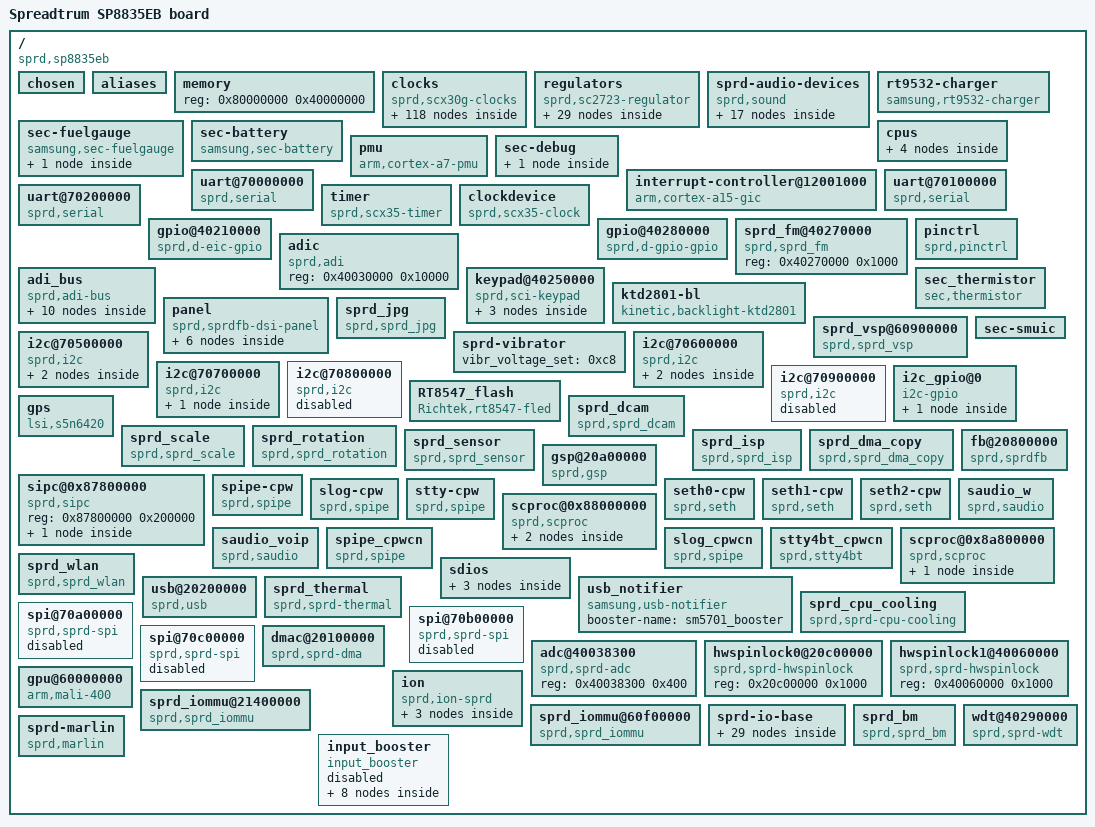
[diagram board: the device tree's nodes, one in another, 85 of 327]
/dts-v1/;

/memreserve/	0x0000000087800000 0x0000000000200000;
/memreserve/	0x0000000088000000 0x0000000001c00000;
/memreserve/	0x000000008a800000 0x0000000000201000;
/memreserve/	0x000000009f8ad000 0x0000000000465000;
/memreserve/	0x000000009fd12000 0x00000000002ee000;
/ {
	#address-cells = <0x01>;
	#size-cells = <0x01>;
	model = "Spreadtrum SP8835EB board";
	compatible = "sprd,sp8835eb";
	sprd,sc-id = <0x227e 0x00 0x20000>;
	interrupt-parent = <0x01>;

	chosen {
		bootargs = "loglevel=0 init=/init root=/dev/ram0 rw";
		linux,initrd-start = <0x85500000>;
		linux,initrd-end = <0x855a3212>;
	};

	aliases {
		serial0 = "/uart@70000000";
		serial1 = "/uart@70100000";
		serial2 = "/uart@70200000";
		i2c0 = "/i2c@70500000";
		i2c1 = "/i2c@70600000";
		i2c2 = "/i2c@70700000";
		i2c_gpio4 = "/i2c_gpio@0";
		lcd0 = "/fb@20800000";
		spi0 = "/spi@70a00000";
		spi1 = "/spi@70b00000";
		spi2 = "/spi@70c00000";
		hwspinlock0 = "/hwspinlock0@20c00000";
		hwspinlock1 = "/hwspinlock1@40060000";
	};

	memory {
		#address-cells = <0x01>;
		#size-cells = <0x01>;
		device_type = "memory";
		reg = <0x80000000 0x40000000>;
	};

	clocks {
		compatible = "sprd,scx30g-clocks";
		#address-cells = <0x01>;
		#size-cells = <0x01>;

		ext_26m {
			compatible = "sprd,fixed-clock";
			#clock-cells = <0x00>;
			clock-frequency = <0x18cba80>;
			clock-output-names = "ext_26m";
			linux,phandle = <0x09>;
			phandle = <0x09>;
		};

		ext_32k {
			compatible = "sprd,fixed-clock";
			#clock-cells = <0x00>;
			clock-frequency = <0x8000>;
			clock-output-names = "ext_32k";
			linux,phandle = <0x12>;
			phandle = <0x12>;
		};

		clk_mpll {
			compatible = "sprd,adjustable-pll-clock";
			#clock-cells = <0x00>;
			reg = <0x402e3070 0x7ff 0x402b0094 0x01>;
			clock-output-names = "clk_mpll";
			linux,phandle = <0x03>;
			phandle = <0x03>;
		};

		clk_dpll {
			compatible = "sprd,adjustable-pll-clock";
			#clock-cells = <0x00>;
			reg = <0x402e3074 0x7ff 0x402b0098 0x01>;
			clock-output-names = "clk_dpll";
			linux,phandle = <0x04>;
			phandle = <0x04>;
		};

		clk_tdpll {
			compatible = "sprd,adjustable-pll-clock";
			#clock-cells = <0x00>;
			reg = <0x402e3078 0x7ff 0x402b009c 0x01>;
			clock-output-names = "clk_tdpll";
			linux,phandle = <0x07>;
			phandle = <0x07>;
		};

		clk_wpll {
			compatible = "sprd,adjustable-pll-clock";
			#clock-cells = <0x00>;
			reg = <0x402e301c 0x7ff 0x402b00a0 0x01>;
			clock-output-names = "clk_wpll";
			linux,phandle = <0x02>;
			phandle = <0x02>;
		};

		clk_cpll {
			compatible = "sprd,adjustable-pll-clock";
			#clock-cells = <0x00>;
			reg = <0x402e307c 0x7ff 0x402b00a4 0x01>;
			clock-output-names = "clk_cpll";
			linux,phandle = <0x06>;
			phandle = <0x06>;
		};

		clk_wifipll {
			compatible = "sprd,adjustable-pll-clock";
			#clock-cells = <0x00>;
			reg = <0x402e3080 0x7ff 0x402b00a8 0x01>;
			clock-output-names = "clk_wifipll";
			linux,phandle = <0x05>;
			phandle = <0x05>;
		};

		clk_460m8 {
			compatible = "sprd,fixed-factor-clock";
			#clock-cells = <0x00>;
			clock-mult = <0x01>;
			clock-div = <0x02>;
			clocks = <0x02>;
			clock-output-names = "clk_460m8";
			linux,phandle = <0x21>;
			phandle = <0x21>;
		};

		clk_300m {
			compatible = "sprd,fixed-factor-clock";
			#clock-cells = <0x00>;
			clock-mult = <0x01>;
			clock-div = <0x03>;
			clocks = <0x03>;
			clock-output-names = "clk_300m";
		};

		clk_37m5 {
			compatible = "sprd,fixed-factor-clock";
			#clock-cells = <0x00>;
			clock-mult = <0x01>;
			clock-div = <0x18>;
			clocks = <0x03>;
			clock-output-names = "clk_37m5";
			linux,phandle = <0x16>;
			phandle = <0x16>;
		};

		clk_66m_d {
			compatible = "sprd,fixed-factor-clock";
			#clock-cells = <0x00>;
			clock-mult = <0x01>;
			clock-div = <0x08>;
			clocks = <0x04>;
			clock-output-names = "clk_66m_d";
		};

		clk_51m2_w {
			compatible = "sprd,fixed-factor-clock";
			#clock-cells = <0x00>;
			clock-mult = <0x01>;
			clock-div = <0x12>;
			clocks = <0x02>;
			clock-output-names = "clk_51m2_w";
			linux,phandle = <0x15>;
			phandle = <0x15>;
		};

		clk_40m_wf1 {
			compatible = "sprd,fixed-factor-clock";
			#clock-cells = <0x00>;
			clock-mult = <0x01>;
			clock-div = <0x16>;
			clocks = <0x05>;
			clock-output-names = "clk_40m_wf1";
			linux,phandle = <0x17>;
			phandle = <0x17>;
		};

		clk_312m {
			compatible = "sprd,fixed-factor-clock";
			#clock-cells = <0x00>;
			clock-mult = <0x01>;
			clock-div = <0x02>;
			clocks = <0x06>;
			clock-output-names = "clk_312m";
			linux,phandle = <0x1c>;
			phandle = <0x1c>;
		};

		clk_208m {
			compatible = "sprd,fixed-factor-clock";
			#clock-cells = <0x00>;
			clock-mult = <0x01>;
			clock-div = <0x03>;
			clocks = <0x06>;
			clock-output-names = "clk_208m";
			linux,phandle = <0x20>;
			phandle = <0x20>;
		};

		clk_104m {
			compatible = "sprd,fixed-factor-clock";
			#clock-cells = <0x00>;
			clock-mult = <0x01>;
			clock-div = <0x06>;
			clocks = <0x06>;
			clock-output-names = "clk_104m";
		};

		clk_52m {
			compatible = "sprd,fixed-factor-clock";
			#clock-cells = <0x00>;
			clock-mult = <0x01>;
			clock-div = <0x0c>;
			clocks = <0x06>;
			clock-output-names = "clk_52m";
			linux,phandle = <0x14>;
			phandle = <0x14>;
		};

		clk_768m {
			compatible = "sprd,fixed-factor-clock";
			#clock-cells = <0x00>;
			clock-mult = <0x01>;
			clock-div = <0x02>;
			clocks = <0x07>;
			clock-output-names = "clk_768m";
			linux,phandle = <0x08>;
			phandle = <0x08>;
		};

		clk_512m {
			compatible = "sprd,fixed-factor-clock";
			#clock-cells = <0x00>;
			clock-mult = <0x01>;
			clock-div = <0x03>;
			clocks = <0x07>;
			clock-output-names = "clk_512m";
			linux,phandle = <0x22>;
			phandle = <0x22>;
		};

		clk_384m {
			compatible = "sprd,fixed-factor-clock";
			#clock-cells = <0x00>;
			clock-mult = <0x01>;
			clock-div = <0x02>;
			clocks = <0x08>;
			clock-output-names = "clk_384m";
			linux,phandle = <0x1d>;
			phandle = <0x1d>;
		};

		clk_256m {
			compatible = "sprd,fixed-factor-clock";
			#clock-cells = <0x00>;
			clock-mult = <0x01>;
			clock-div = <0x03>;
			clocks = <0x08>;
			clock-output-names = "clk_256m";
			linux,phandle = <0x1b>;
			phandle = <0x1b>;
		};

		clk_192m {
			compatible = "sprd,fixed-factor-clock";
			#clock-cells = <0x00>;
			clock-mult = <0x01>;
			clock-div = <0x04>;
			clocks = <0x08>;
			clock-output-names = "clk_192m";
			linux,phandle = <0x1a>;
			phandle = <0x1a>;
		};

		clk_153m6 {
			compatible = "sprd,fixed-factor-clock";
			#clock-cells = <0x00>;
			clock-mult = <0x01>;
			clock-div = <0x05>;
			clocks = <0x08>;
			clock-output-names = "clk_153m6";
			linux,phandle = <0x0d>;
			phandle = <0x0d>;
		};

		clk_128m {
			compatible = "sprd,fixed-factor-clock";
			#clock-cells = <0x00>;
			clock-mult = <0x01>;
			clock-div = <0x06>;
			clocks = <0x08>;
			clock-output-names = "clk_128m";
			linux,phandle = <0x0c>;
			phandle = <0x0c>;
		};

		clk_96m {
			compatible = "sprd,fixed-factor-clock";
			#clock-cells = <0x00>;
			clock-mult = <0x01>;
			clock-div = <0x08>;
			clocks = <0x08>;
			clock-output-names = "clk_96m";
			linux,phandle = <0x0b>;
			phandle = <0x0b>;
		};

		clk_76m8 {
			compatible = "sprd,fixed-factor-clock";
			#clock-cells = <0x00>;
			clock-mult = <0x01>;
			clock-div = <0x0a>;
			clocks = <0x08>;
			clock-output-names = "clk_76m8";
			linux,phandle = <0x0e>;
			phandle = <0x0e>;
		};

		clk_64m {
			compatible = "sprd,fixed-factor-clock";
			#clock-cells = <0x00>;
			clock-mult = <0x01>;
			clock-div = <0x0c>;
			clocks = <0x08>;
			clock-output-names = "clk_64m";
			linux,phandle = <0x11>;
			phandle = <0x11>;
		};

		clk_51m2 {
			compatible = "sprd,fixed-factor-clock";
			#clock-cells = <0x00>;
			clock-mult = <0x01>;
			clock-div = <0x0f>;
			clocks = <0x08>;
			clock-output-names = "clk_51m2";
			linux,phandle = <0x10>;
			phandle = <0x10>;
		};

		clk_48m {
			compatible = "sprd,fixed-factor-clock";
			#clock-cells = <0x00>;
			clock-mult = <0x01>;
			clock-div = <0x10>;
			clocks = <0x08>;
			clock-output-names = "clk_48m";
			linux,phandle = <0x13>;
			phandle = <0x13>;
		};

		clk_38m4 {
			compatible = "sprd,fixed-factor-clock";
			#clock-cells = <0x00>;
			clock-mult = <0x01>;
			clock-div = <0x14>;
			clocks = <0x08>;
			clock-output-names = "clk_38m4";
			linux,phandle = <0x0f>;
			phandle = <0x0f>;
		};

		clk_24m {
			compatible = "sprd,fixed-factor-clock";
			#clock-cells = <0x00>;
			clock-mult = <0x01>;
			clock-div = <0x20>;
			clocks = <0x08>;
			clock-output-names = "clk_24m";
			linux,phandle = <0x1f>;
			phandle = <0x1f>;
		};

		clk_12m {
			compatible = "sprd,fixed-factor-clock";
			#clock-cells = <0x00>;
			clock-mult = <0x01>;
			clock-div = <0x40>;
			clocks = <0x08>;
			clock-output-names = "clk_12m";
			linux,phandle = <0x1e>;
			phandle = <0x1e>;
		};

		clk_mcu {
			compatible = "sprd,composite-dev-clock";
			#clock-cells = <0x00>;
			reg = <0x20d03000 0x07 0x20d03000 0x70>;
			clocks = <0x09 0x04 0x06 0x08 0x05 0x02 0x03>;
			clock-output-names = "clk_mcu";
			linux,phandle = <0x0a>;
			phandle = <0x0a>;
		};

		clk_ca7_axi {
			compatible = "sprd,divider-clock";
			#clock-cells = <0x00>;
			reg = <0x20d03000 0x700>;
			clocks = <0x0a>;
			clock-output-names = "clk_ca7_axi";
		};

		clk_ca7_dbg {
			compatible = "sprd,divider-clock";
			#clock-cells = <0x00>;
			reg = <0x20d03000 0x70000 0x20d00014 0x100>;
			clocks = <0x0a>;
			clock-output-names = "clk_ca7_dbg";
		};

		clk_emc {
			compatible = "sprd,composite-dev-clock";
			#clock-cells = <0x00>;
			reg = <0x402d0024 0x03 0x402d0024 0x300>;
			clocks = <0x09 0x06 0x07 0x04>;
			clock-output-names = "clk_emc";
		};

		clk_pub_ahb {
			compatible = "sprd,muxed-clock";
			#clock-cells = <0x00>;
			reg = <0x402d0020 0x03>;
			clocks = <0x09 0x0b 0x0c 0x0d>;
			clock-output-names = "clk_pub_ahb";
		};

		clk_aon_apb {
			compatible = "sprd,composite-dev-clock";
			#clock-cells = <0x00>;
			reg = <0x402d0028 0x03 0x402d0028 0x300>;
			clocks = <0x09 0x0e 0x0b 0x0c>;
			clock-output-names = "clk_aon_apb";
			linux,phandle = <0x19>;
			phandle = <0x19>;
		};

		clk_adi {
			compatible = "sprd,muxed-clock";
			#clock-cells = <0x00>;
			reg = <0x402d0034 0x03 0x402e0000 0x10000>;
			clocks = <0x09 0x0f 0x10 0x11>;
			clock-output-names = "clk_adi";
		};

		clk_aux0 {
			compatible = "sprd,composite-dev-clock";
			#clock-cells = <0x00>;
			reg = <0x402e3020 0x07 0x402e3020 0xf0000 0x402e0004 0x04>;
			clocks = <0x12 0x09 0x09 0x13 0x14 0x15 0x16 0x17>;
			clock-output-names = "clk_aux0";
		};

		clk_aux1 {
			compatible = "sprd,composite-dev-clock";
			#clock-cells = <0x00>;
			reg = <0x402e3020 0x70 0x402e3020 0xf00000 0x402e0004 0x08>;
			clocks = <0x12 0x09 0x09 0x13 0x14 0x15 0x16 0x17>;
			clock-output-names = "clk_aux1";
		};

		clk_aux2 {
			compatible = "sprd,composite-dev-clock";
			#clock-cells = <0x00>;
			reg = <0x402e3020 0x700 0x402e3020 0xf000000 0x402e0004 0x10>;
			clocks = <0x12 0x09 0x09 0x13 0x14 0x15 0x16 0x17>;
			clock-output-names = "clk_aux2";
		};

		clk_probe {
			compatible = "sprd,composite-dev-clock";
			#clock-cells = <0x00>;
			reg = <0x402e3020 0x7000 0x402e3020 0xf0000000 0x402e0004 0x20>;
			clocks = <0x12 0x09 0x09 0x13 0x14 0x15 0x16 0x17>;
			clock-output-names = "clk_probe";
		};

		clk_pwm0 {
			compatible = "sprd,muxed-clock";
			#clock-cells = <0x00>;
			reg = <0x402d0038 0x01 0x402e0000 0x10>;
			clocks = <0x12 0x09>;
			clock-output-names = "clk_pwm0";
		};

		clk_pwm1 {
			compatible = "sprd,muxed-clock";
			#clock-cells = <0x00>;
			reg = <0x402d003c 0x01 0x402e0000 0x20>;
			clocks = <0x12 0x09>;
			clock-output-names = "clk_pwm1";
		};

		clk_pwm2 {
			compatible = "sprd,muxed-clock";
			#clock-cells = <0x00>;
			reg = <0x402d0040 0x01 0x402e0000 0x40>;
			clocks = <0x12 0x09>;
			clock-output-names = "clk_pwm2";
		};

		clk_pwm3 {
			compatible = "sprd,muxed-clock";
			#clock-cells = <0x00>;
			reg = <0x402d0044 0x01 0x402e0000 0x80>;
			clocks = <0x12 0x09>;
			clock-output-names = "clk_pwm3";
		};

		clk_thm {
			compatible = "sprd,muxed-clock";
			#clock-cells = <0x00>;
			reg = <0x402d0048 0x01 0x402e0004 0x02>;
			clocks = <0x12 0x09>;
			clock-output-names = "clk_thm";
		};

		clk_efuse {
			compatible = "sprd,gate-clock";
			#clock-cells = <0x00>;
			reg = <0x402e0000 0x2000>;
			clocks = <0x09>;
			clock-output-names = "clk_efuse";
		};

		clk_mspi {
			compatible = "sprd,muxed-clock";
			#clock-cells = <0x00>;
			reg = <0x402d0054 0x03 0x402e0000 0x800000>;
			clocks = <0x09 0x14 0x0e 0x0b>;
			clock-output-names = "clk_mspi";
		};

		clk_i2c {
			compatible = "sprd,muxed-clock";
			#clock-cells = <0x00>;
			reg = <0x402d0058 0x03 0x402e0000 0x80000000>;
			clocks = <0x09 0x13 0x10 0x0d>;
			clock-output-names = "clk_i2c";
		};

		clk_avs0 {
			compatible = "sprd,muxed-clock";
			#clock-cells = <0x00>;
			reg = <0x402d005c 0x03 0x402e0000 0x40>;
			clocks = <0x09 0x13 0x10 0x0b>;
			clock-output-names = "clk_avs0";
		};

		clk_avs1 {
			compatible = "sprd,muxed-clock";
			#clock-cells = <0x00>;
			reg = <0x402d0060 0x03 0x402e0000 0x80>;
			clocks = <0x09 0x13 0x10 0x0b>;
			clock-output-names = "clk_avs1";
		};

		clk_aud {
			compatible = "sprd,gate-clock";
			#clock-cells = <0x00>;
			reg = <0x402e0000 0x40000>;
			clocks = <0x09>;
			clock-output-names = "clk_aud";
		};

		clk_audif {
			compatible = "sprd,muxed-clock";
			#clock-cells = <0x00>;
			reg = <0x402d002c 0x03 0x402e0000 0x20000>;
			clocks = <0x09 0x0f 0x10>;
			clock-output-names = "clk_audif";
		};

		clk_vbc {
			compatible = "sprd,gate-clock";
			#clock-cells = <0x00>;
			reg = <0x402e0000 0x80000>;
			clocks = <0x09>;
			clock-output-names = "clk_vbc";
		};

		clk_ca7_dap {
			compatible = "sprd,muxed-clock";
			#clock-cells = <0x00>;
			reg = <0x402d004c 0x03 0x402e0000 0x40000000>;
			clocks = <0x09 0x0e 0x0c 0x0d>;
			clock-output-names = "clk_ca7_dap";
		};

		clk_ca7_ts {
			compatible = "sprd,muxed-clock";
			#clock-cells = <0x00>;
			reg = <0x402d0050 0x03 0x402e0000 0x10000000>;
			clocks = <0x12 0x09 0x0c 0x0d>;
			clock-output-names = "clk_ca7_ts";
		};

		clk_fm_in {
			compatible = "sprd,fixed-clock";
			#clock-cells = <0x00>;
			clock-frequency = <0x3d09000>;
			clock-output-names = "clk_fm_in";
			linux,phandle = <0x18>;
			phandle = <0x18>;
		};

		clk_fm {
			compatible = "sprd,gate-clock";
			#clock-cells = <0x00>;
			reg = <0x402e0000 0x02>;
			clocks = <0x18>;
			clock-output-names = "clk_fm";
		};

		clk_disp_emc {
			compatible = "sprd,gate-clock";
			#clock-cells = <0x00>;
			reg = <0x402e0004 0x800>;
			clocks = <0x19>;
			clock-output-names = "clk_disp_emc";
			linux,phandle = <0x43>;
			phandle = <0x43>;
		};

		clk_zip_emc {
			compatible = "sprd,gate-clock";
			#clock-cells = <0x00>;
			reg = <0x402e0004 0x1000>;
			clocks = <0x19>;
			clock-output-names = "clk_zip_emc";
		};

		clk_gsp_emc {
			compatible = "sprd,gate-clock";
			#clock-cells = <0x00>;
			reg = <0x402e0004 0x2000>;
			clocks = <0x19>;
			clock-output-names = "clk_gsp_emc";
			linux,phandle = <0x46>;
			phandle = <0x46>;
		};

		clk_ap_ahb {
			compatible = "sprd,muxed-clock";
			#clock-cells = <0x00>;
			reg = <0x71200020 0x03>;
			clocks = <0x09 0x0e 0x0c 0x1a>;
			clock-output-names = "clk_ap_ahb";
		};

		clk_ap_apb {
			compatible = "sprd,muxed-clock";
			#clock-cells = <0x00>;
			reg = <0x71200024 0x03>;
			clocks = <0x09 0x11 0x0b 0x0c>;
			clock-output-names = "clk_ap_apb";
		};

		clk_gsp {
			compatible = "sprd,muxed-clock";
			#clock-cells = <0x00>;
			reg = <0x71200028 0x03 0x20d00000 0x08>;
			clocks = <0x0b 0x0d 0x1a 0x1b>;
			clock-output-names = "clk_gsp";
			linux,phandle = <0x45>;
			phandle = <0x45>;
		};

		clk_dispc0 {
			compatible = "sprd,composite-dev-clock";
			#clock-cells = <0x00>;
			reg = <0x7120002c 0x03 0x7120002c 0x700 0x20d00000 0x02>;
			clocks = <0x0d 0x1a 0x1b 0x1c>;
			clock-output-names = "clk_dispc0";
			linux,phandle = <0x40>;
			phandle = <0x40>;
		};

		clk_dispc0_dbi {
			compatible = "sprd,composite-dev-clock";
			#clock-cells = <0x00>;
			reg = <0x71200030 0x03 0x71200030 0x700 0x20d00000 0x02>;
			clocks = <0x0c 0x0d 0x1a 0x1b>;
			clock-output-names = "clk_dispc0_dbi";
			linux,phandle = <0x41>;
			phandle = <0x41>;
		};

		clk_dispc0_dpi {
			compatible = "sprd,composite-dev-clock";
			#clock-cells = <0x00>;
			reg = <0x71200034 0x03 0x71200034 0xff00 0x20d00000 0x02>;
			clocks = <0x0c 0x0d 0x1a 0x1d>;
			clock-output-names = "clk_dispc0_dpi";
			linux,phandle = <0x42>;
			phandle = <0x42>;
		};

		clk_dispc1 {
			compatible = "sprd,composite-dev-clock";
			#clock-cells = <0x00>;
			reg = <0x71200038 0x03 0x71200038 0x700 0x20d00000 0x04>;
			clocks = <0x0d 0x1a 0x1b 0x1c>;
			clock-output-names = "clk_dispc1";
		};

		clk_dispc1_dbi {
			compatible = "sprd,composite-dev-clock";
			#clock-cells = <0x00>;
			reg = <0x7120003c 0x03 0x7120003c 0x700 0x20d00000 0x04>;
			clocks = <0x0c 0x0d 0x1a 0x1b>;
			clock-output-names = "clk_dispc1_dbi";
		};

		clk_dispc1_dpi {
			compatible = "sprd,composite-dev-clock";
			#clock-cells = <0x00>;
			reg = <0x71200040 0x03 0x71200040 0xff00 0x20d00000 0x04>;
			clocks = <0x0c 0x0d 0x1a 0x1d>;
			clock-output-names = "clk_dispc1_dpi";
		};

		clk_nandc_ecc {
			compatible = "sprd,muxed-clock";
			#clock-cells = <0x00>;
			reg = <0x71200044 0x01 0x20d00000 0x80000 0x20d00000 0x20000>;
			clocks = <0x0d 0x1a>;
			clock-output-names = "clk_nandc_ecc";
		};

		clk_nandc_2x {
			compatible = "sprd,composite-dev-clock";
			#clock-cells = <0x00>;
			reg = <0x20d03038 0x03 0x20d03038 0x0c 0x20d00000 0xe0000>;
			clocks = <0x09 0x0d 0x1a 0x1b>;
			clock-output-names = "clk_nandc_2x";
		};

		clk_sdio0 {
			compatible = "sprd,composite-dev-clock";
			#clock-cells = <0x00>;
			reg = <0x71200048 0x03 0x71200048 0x700 0x20d00000 0x100>;
			clocks = <0x09 0x1b 0x1c 0x1a>;
			clock-output-names = "clk_sdio0";
			linux,phandle = <0x48>;
			phandle = <0x48>;
		};

		clk_sdio1 {
			compatible = "sprd,muxed-clock";
			#clock-cells = <0x00>;
			reg = <0x7120004c 0x03 0x20d00000 0x200>;
			clocks = <0x13 0x0e 0x0b 0x0c>;
			clock-output-names = "clk_sdio1";
			linux,phandle = <0x49>;
			phandle = <0x49>;
		};

		clk_sdio2 {
			compatible = "sprd,muxed-clock";
			#clock-cells = <0x00>;
			reg = <0x71200050 0x03 0x20d00000 0x400>;
			clocks = <0x13 0x0e 0x0b 0x0c>;
			clock-output-names = "clk_sdio2";
		};

		clk_emmc {
			compatible = "sprd,muxed-clock";
			#clock-cells = <0x00>;
			reg = <0x71200054 0x03 0x20d00000 0x800>;
			clocks = <0x09 0x1b 0x1c 0x1a>;
			clock-output-names = "clk_emmc";
			linux,phandle = <0x47>;
			phandle = <0x47>;
		};

		clk_gps {
			compatible = "sprd,muxed-clock";
			#clock-cells = <0x00>;
			reg = <0x71200058 0x01 0x20d00000 0x1000>;
			clocks = <0x11 0x0e>;
			clock-output-names = "clk_gps";
		};

		clk_usb_ref {
			compatible = "sprd,muxed-clock";
			#clock-cells = <0x00>;
			reg = <0x71200060 0x01 0x20d00000 0x10>;
			clocks = <0x1e 0x1f>;
			clock-output-names = "clk_usb_ref";
		};

		clk_uart0 {
			compatible = "sprd,composite-dev-clock";
			#clock-cells = <0x00>;
			reg = <0x71200064 0x03 0x71200064 0x700 0x71300000 0x2000>;
			clocks = <0x09 0x13 0x10 0x0b>;
			clock-output-names = "clk_uart0";
		};

		clk_uart1 {
			compatible = "sprd,composite-dev-clock";
			#clock-cells = <0x00>;
			reg = <0x71200068 0x03 0x71200068 0x700 0x71300000 0x4000>;
			clocks = <0x09 0x13 0x10 0x0b>;
			clock-output-names = "clk_uart1";
		};

		clk_uart2 {
			compatible = "sprd,composite-dev-clock";
			#clock-cells = <0x00>;
			reg = <0x7120006c 0x03 0x7120006c 0x700 0x71300000 0x8000>;
			clocks = <0x09 0x13 0x10 0x0b>;
			clock-output-names = "clk_uart2";
		};

		clk_uart3 {
			compatible = "sprd,composite-dev-clock";
			#clock-cells = <0x00>;
			reg = <0x71200070 0x03 0x71200070 0x700 0x71300000 0x10000>;
			clocks = <0x09 0x13 0x10 0x0b>;
			clock-output-names = "clk_uart3";
		};

		clk_uart4 {
			compatible = "sprd,composite-dev-clock";
			#clock-cells = <0x00>;
			reg = <0x71200074 0x03 0x71200074 0x700 0x71300000 0x20000>;
			clocks = <0x09 0x13 0x10 0x0b>;
			clock-output-names = "clk_uart4";
		};

		clk_i2c0 {
			compatible = "sprd,composite-dev-clock";
			#clock-cells = <0x00>;
			reg = <0x71200078 0x03 0x71200078 0x700 0x71300000 0x100>;
			clocks = <0x09 0x13 0x10 0x0d>;
			clock-output-names = "clk_i2c0";
		};

		clk_i2c1 {
			compatible = "sprd,composite-dev-clock";
			#clock-cells = <0x00>;
			reg = <0x7120007c 0x03 0x7120007c 0x700 0x71300000 0x200>;
			clocks = <0x09 0x13 0x10 0x0d>;
			clock-output-names = "clk_i2c1";
		};

		clk_i2c2 {
			compatible = "sprd,composite-dev-clock";
			#clock-cells = <0x00>;
			reg = <0x71200080 0x03 0x71200080 0x700 0x71300000 0x400>;
			clocks = <0x09 0x13 0x10 0x0d>;
			clock-output-names = "clk_i2c2";
		};

		clk_i2c3 {
			compatible = "sprd,composite-dev-clock";
			#clock-cells = <0x00>;
			reg = <0x71200084 0x03 0x71200084 0x700 0x71300000 0x800>;
			clocks = <0x09 0x13 0x10 0x0d>;
			clock-output-names = "clk_i2c3";
		};

		clk_i2c4 {
			compatible = "sprd,composite-dev-clock";
			#clock-cells = <0x00>;
			reg = <0x71200088 0x03 0x71200088 0x700 0x71300000 0x1000>;
			clocks = <0x09 0x13 0x10 0x0d>;
			clock-output-names = "clk_i2c4";
		};

		clk_spi0 {
			compatible = "sprd,composite-dev-clock";
			#clock-cells = <0x00>;
			reg = <0x7120008c 0x03 0x7120008c 0x700 0x71300000 0x20>;
			clocks = <0x09 0x0b 0x0d 0x1a>;
			clock-output-names = "clk_spi0";
		};

		clk_spi1 {
			compatible = "sprd,composite-dev-clock";
			#clock-cells = <0x00>;
			reg = <0x71200090 0x03 0x71200090 0x700 0x71300000 0x40>;
			clocks = <0x09 0x0b 0x0d 0x1a>;
			clock-output-names = "clk_spi1";
		};

		clk_spi2 {
			compatible = "sprd,composite-dev-clock";
			#clock-cells = <0x00>;
			reg = <0x71200094 0x03 0x71200094 0x700 0x71300000 0x80>;
			clocks = <0x09 0x0b 0x0d 0x1a>;
			clock-output-names = "clk_spi2";
			linux,phandle = <0x44>;
			phandle = <0x44>;
		};

		clk_iis0 {
			compatible = "sprd,composite-dev-clock";
			#clock-cells = <0x00>;
			reg = <0x71200098 0x03 0x71200098 0x700 0x71300000 0x02>;
			clocks = <0x09 0x0c 0x0d>;
			clock-output-names = "clk_iis0";
		};

		clk_iis1 {
			compatible = "sprd,composite-dev-clock";
			#clock-cells = <0x00>;
			reg = <0x7120009c 0x03 0x7120009c 0x700 0x71300000 0x04>;
			clocks = <0x09 0x0c 0x0d>;
			clock-output-names = "clk_iis1";
		};

		clk_iis2 {
			compatible = "sprd,composite-dev-clock";
			#clock-cells = <0x00>;
			reg = <0x712000a0 0x03 0x712000a0 0x700 0x71300000 0x08>;
			clocks = <0x09 0x0c 0x0d>;
			clock-output-names = "clk_iis2";
		};

		clk_iis3 {
			compatible = "sprd,composite-dev-clock";
			#clock-cells = <0x00>;
			reg = <0x712000a4 0x03 0x712000a4 0x700 0x71300000 0x10>;
			clocks = <0x09 0x0c 0x0d>;
			clock-output-names = "clk_iis3";
		};

		clk_zipenc {
			compatible = "sprd,muxed-clock";
			#clock-cells = <0x00>;
			reg = <0x712000a8 0x03 0x20d00000 0x100000>;
			clocks = <0x0b 0x0d 0x1a 0x1b>;
			clock-output-names = "clk_zipenc";
		};

		clk_zipdec {
			compatible = "sprd,muxed-clock";
			#clock-cells = <0x00>;
			reg = <0x712000ac 0x03 0x20d00000 0x200000>;
			clocks = <0x0b 0x0d 0x1a 0x1b>;
			clock-output-names = "clk_zipdec";
		};

		clk_gpu_axi {
			compatible = "sprd,gate-clock";
			#clock-cells = <0x00>;
			reg = <0x402e0000 0x8000000 0x402b0021 0x2000000>;
			clocks = <0x19>;
			clock-output-names = "clk_gpu_axi";
			linux,phandle = <0x4b>;
			phandle = <0x4b>;
		};

		clk_gpu {
			compatible = "sprd,composite-dev-clock";
			#clock-cells = <0x00>;
			reg = <0x60100004 0x07 0x60100004 0x30>;
			clocks = <0x0d 0x20 0x1b 0x1c 0x1d 0x21 0x22>;
			clock-output-names = "clk_gpu";
			linux,phandle = <0x4c>;
			phandle = <0x4c>;
		};

		clk_ccir_in {
			compatible = "sprd,fixed-clock";
			#clock-cells = <0x00>;
			clock-frequency = <0x3d09000>;
			clock-output-names = "clk_ccir_in";
			linux,phandle = <0x27>;
			phandle = <0x27>;
		};

		clk_mm {
			compatible = "sprd,gate-clock";
			#clock-cells = <0x00>;
			reg = <0x402e0000 0x2000000 0x402b001d 0x2000000>;
			clocks = <0x19>;
			clock-output-names = "clk_mm";
			linux,phandle = <0x23>;
			phandle = <0x23>;
		};

		clk_mm_ahb {
			compatible = "sprd,muxed-clock";
			#clock-cells = <0x00>;
			reg = <0x60e00020 0x03>;
			clocks = <0x09 0x0b 0x0c 0x0d>;
			clock-output-names = "clk_mm_ahb";
			mm-domain;
			linux,phandle = <0x25>;
			phandle = <0x25>;
		};

		clk_mm_axi {
			compatible = "sprd,gate-clock";
			#clock-cells = <0x00>;
			reg = <0x60d00008 0x80>;
			clocks = <0x23>;
			clock-output-names = "clk_mm_axi";
			#mm-domain;
			linux,phandle = <0x24>;
			phandle = <0x24>;
		};

		clk_mm_mtx_axi {
			compatible = "sprd,gate-clock";
			#clock-cells = <0x00>;
			reg = <0x60d00008 0x100>;
			clocks = <0x24>;
			clock-output-names = "clk_mm_mtx_axi";
			mm-domain;
		};

		clk_mmu {
			compatible = "sprd,gate-clock";
			#clock-cells = <0x00>;
			reg = <0x60d00000 0x80>;
			clocks = <0x25>;
			clock-output-names = "clk_mmu";
			mm-domain;
			linux,phandle = <0x4d>;
			phandle = <0x4d>;
		};

		clk_mm_ckg {
			compatible = "sprd,gate-clock";
			#clock-cells = <0x00>;
			reg = <0x60d00000 0x40>;
			clocks = <0x25>;
			clock-output-names = "clk_mm_ckg";
			mm-domain;
		};

		clk_jpg {
			compatible = "sprd,muxed-clock";
			#clock-cells = <0x00>;
			reg = <0x60e00038 0x03 0x60d00008 0x40 0x60d00000 0x20>;
			clocks = <0x0e 0x0c 0x1a 0x1b>;
			clock-output-names = "clk_jpg";
			mm-domain;
			linux,phandle = <0x3a>;
			phandle = <0x3a>;
		};

		clk_csi {
			compatible = "sprd,gate-clock";
			#clock-cells = <0x00>;
			reg = <0x60d00008 0x02 0x60d00000 0x10>;
			clocks = <0x25>;
			clock-output-names = "clk_csi";
			mm-domain;
			linux,phandle = <0x26>;
			phandle = <0x26>;
		};

		clk_dcam_mipi {
			compatible = "sprd,gate-clock";
			#clock-cells = <0x00>;
			reg = <0x60d00008 0x01>;
			clocks = <0x26>;
			clock-output-names = "clk_dcam_mipi";
			mm-domain;
			linux,phandle = <0x3e>;
			phandle = <0x3e>;
		};

		clk_vsp {
			compatible = "sprd,muxed-clock";
			#clock-cells = <0x00>;
			reg = <0x60e00030 0x03 0x60d00008 0x20 0x60d00000 0x08>;
			clocks = <0x0e 0x0c 0x1a>;
			clock-output-names = "clk_vsp";
			mm-domain;
			linux,phandle = <0x39>;
			phandle = <0x39>;
		};

		clk_isp {
			compatible = "sprd,muxed-clock";
			#clock-cells = <0x00>;
			reg = <0x60e00034 0x03 0x60d00008 0x10 0x60d00000 0x04>;
			clocks = <0x0e 0x0c 0x1a 0x1b>;
			clock-output-names = "clk_isp";
			mm-domain;
			linux,phandle = <0x3f>;
			phandle = <0x3f>;
		};

		clk_ccir {
			compatible = "sprd,muxed-clock";
			#clock-cells = <0x00>;
			reg = <0x60e00028 0x10000 0x60d00000 0x02>;
			clocks = <0x1f 0x27>;
			clock-output-names = "clk_ccir";
			mm-domain;
			linux,phandle = <0x3d>;
			phandle = <0x3d>;
		};

		clk_sensor {
			compatible = "sprd,composite-dev-clock";
			#clock-cells = <0x00>;
			reg = <0x60e00024 0x03 0x60e00024 0x700 0x60d00008 0x04>;
			clocks = <0x09 0x13 0x0e 0x0b>;
			clock-output-names = "clk_sensor";
			mm-domain;
			linux,phandle = <0x3c>;
			phandle = <0x3c>;
		};

		clk_dcam {
			compatible = "sprd,muxed-clock";
			#clock-cells = <0x00>;
			reg = <0x60e0002c 0x03 0x60d00008 0x08 0x60d00000 0x01>;
			clocks = <0x0e 0x0c 0x1a 0x1b>;
			clock-output-names = "clk_dcam";
			mm-domain;
			linux,phandle = <0x3b>;
			phandle = <0x3b>;
		};

		clk_vpp {
			compatible = "sprd,muxed-clock";
			#clock-cells = <0x00>;
			reg = <0x60e0003c 0x03 0x60d00008 0x200 0x60d00000 0x100>;
			clocks = <0x0e 0x0c 0x1a 0x1b>;
			clock-output-names = "clk_vpp";
			mm-domain;
		};
	};

	regulators {
		compatible = "sprd,sc2723-regulator";
		#address-cells = <0x01>;
		#size-cells = <0x01>;

		dummy {
		};

		vddcore {
			regulator-name = "vddcore";
			reg = <0x40038810 0x200 0x40038a00 0x3ff 0x400388c0 0x01>;
			regulator-cal-channel = <0x40038888 0x4000 0x0d>;
			regulator-default-microvolt = <0xdbba0>;
			regulator-step-microvolt = <0xc35>;
			regulator-min-microvolt = <0x927c0>;
			regulator-max-microvolt = <0x2faf08>;
			regulator-microvolt-offset = <0x00>;
			hide-offset = <0x47e>;
			default-on;
			dcdc;
		};

		vddarm {
			regulator-name = "vddarm";
			reg = <0x40038810 0x400 0x40038a04 0x3ff 0x400388c0 0x04>;
			regulator-cal-channel = <0x40038888 0x2000 0x0d>;
			regulator-default-microvolt = <0xdbba0>;
			regulator-step-microvolt = <0xc35>;
			regulator-min-microvolt = <0x927c0>;
			regulator-max-microvolt = <0x2faf08>;
			regulator-microvolt-offset = <0x00>;
			hide-offset = <0x47e>;
			default-on;
			dcdc;
		};

		vddmem {
			regulator-name = "vddmem";
			reg = <0x40038810 0x800 0x40038a08 0x3ff 0x400388c0 0x08>;
			regulator-cal-channel = <0x40038888 0x6000 0x0d>;
			regulator-default-microvolt = <0x124f80>;
			regulator-step-microvolt = <0xc35>;
			regulator-min-microvolt = <0x927c0>;
			regulator-max-microvolt = <0x2faf08>;
			regulator-microvolt-offset = <0x00>;
			hide-offset = <0x3e8>;
			dcdc;
		};

		vddgen {
			regulator-name = "vddgen";
			reg = <0x40038810 0x1000 0x40038a0c 0x3ff 0x400388c0 0x10>;
			regulator-cal-channel = <0x40038888 0x8000 0x0d>;
			regulator-default-microvolt = <0x249f00>;
			regulator-step-microvolt = <0xc35>;
			regulator-min-microvolt = <0x927c0>;
			regulator-max-microvolt = <0x2faf08>;
			regulator-microvolt-offset = <0x00>;
			hide-offset = <0x3e8>;
			default-on;
			dcdc;
		};

		vddrf {
			regulator-name = "vddrf";
			reg = <0x40038810 0x2000 0x40038a1c 0x3ff 0x400388c0 0x20>;
			regulator-cal-channel = <0x40038888 0xa000 0x0d>;
			regulator-default-microvolt = <0x16e360>;
			regulator-step-microvolt = <0xc35>;
			regulator-min-microvolt = <0x927c0>;
			regulator-max-microvolt = <0x2faf08>;
			regulator-microvolt-offset = <0x00>;
			hide-offset = <0x3e8>;
			default-on;
			dcdc;
		};

		vddwpa {
			regulator-name = "vddwpa";
			reg = <0x40038814 0x4000 0x40038a10 0x07 0x00 0x00>;
			regulator-cal-channel = <0x40038888 0xe000 0x0d>;
			regulator-default-microvolt = <0x2faf08>;
			regulator-step-microvolt = <0xc35>;
			regulator-min-microvolt = <0x2faf08>;
			regulator-max-microvolt = <0x33e140>;
			regulator-microvolt-offset = <0x00>;
			hide-offset = <0x3e8>;
			dcdc;
			status = "disabled";
		};

		vddcon {
			regulator-name = "vddcon";
			reg = <0x40038814 0x2000 0x40038a18 0x3ff 0x00 0x00>;
			regulator-cal-channel = <0x40038888 0xc000 0x0d>;
			regulator-default-microvolt = <0x186a00>;
			regulator-step-microvolt = <0xc35>;
			regulator-min-microvolt = <0x927c0>;
			regulator-max-microvolt = <0x2faf08>;
			regulator-microvolt-offset = <0x00>;
			hide-offset = <0x3e8>;
			dcdc;
		};

		vddrf0 {
			regulator-name = "vddrf0";
			reg = <0x40038810 0x100 0x40038818 0x7f00 0x400388c0 0x800>;
			regulator-cal-channel = <0x40038844 0x04 0x15>;
			regulator-default-microvolt = <0x1b7740>;
			regulator-step-microvolt = <0x186a>;
			regulator-min-microvolt = <0x118c30>;
			regulator-max-microvolt = <0x1da5d8>;
			regulator-microvolt-offset = <0x00>;
			hide-offset = <0x3e8>;
			default-on;
		};

		vddemmccore {
			regulator-name = "vddemmccore";
			reg = <0x40038810 0x80 0x40038834 0xff00 0x400388c0 0x80>;
			regulator-cal-channel = <0x40038844 0x60 0x17>;
			regulator-default-microvolt = <0x2dc6c0>;
			regulator-step-microvolt = <0x2710>;
			regulator-min-microvolt = <0x124f80>;
			regulator-max-microvolt = <0x395f80>;
			regulator-microvolt-offset = <0x00>;
			hide-offset = <0x3e8>;
			default-on;
		};

		vddgen1 {
			regulator-name = "vddgen1";
			reg = <0x40038810 0x40 0x40038824 0x7f00 0x400388c0 0x1000>;
			regulator-cal-channel = <0x40038844 0x05 0x15>;
			regulator-default-microvolt = <0x1b7740>;
			regulator-step-microvolt = <0x186a>;
			regulator-min-microvolt = <0x118c30>;
			regulator-max-microvolt = <0x1dc130>;
			regulator-microvolt-offset = <0x00>;
			hide-offset = <0x3e8>;
			default-on;
		};

		vddgen0 {
			regulator-name = "vddgen0";
			reg = <0x40038810 0x10 0x40038820 0x7f 0x400388c0 0x2000>;
			regulator-cal-channel = <0x40038844 0x06 0x15>;
			regulator-default-microvolt = <0x1b7740>;
			regulator-step-microvolt = <0x186a>;
			regulator-min-microvolt = <0x118c30>;
			regulator-max-microvolt = <0x1dc130>;
			regulator-microvolt-offset = <0x00>;
			hide-offset = <0x3e8>;
			default-on;
		};

		vdddcxo {
			regulator-name = "vdddcxo";
			reg = <0x40038810 0x20 0x40038838 0xff00 0x400388c0 0x100>;
			regulator-cal-channel = <0x40038844 0x80 0x17>;
			regulator-default-microvolt = <0x1b7740>;
			regulator-step-microvolt = <0x2710>;
			regulator-min-microvolt = <0x124f80>;
			regulator-max-microvolt = <0x395f80>;
			regulator-microvolt-offset = <0x00>;
			hide-offset = <0x3e8>;
			default-on;
		};

		vdd25 {
			regulator-name = "vdd25";
			reg = <0x40038810 0x08 0x40038840 0xff 0x400388c0 0x40>;
			regulator-cal-channel = <0x40038844 0x100 0x16>;
			regulator-default-microvolt = <0x2ab980>;
			regulator-step-microvolt = <0x2710>;
			regulator-min-microvolt = <0x124f80>;
			regulator-max-microvolt = <0x395f80>;
			regulator-microvolt-offset = <0x00>;
			hide-offset = <0x3e8>;
		};

		vdd28 {
			regulator-name = "vdd28";
			reg = <0x40038810 0x04 0x40038824 0xff 0x400388c0 0x200>;
			regulator-cal-channel = <0x40038844 0xc0 0x17>;
			regulator-default-microvolt = <0x2ab980>;
			regulator-step-microvolt = <0x2710>;
			regulator-min-microvolt = <0x124f80>;
			regulator-max-microvolt = <0x395f80>;
			regulator-microvolt-offset = <0x00>;
			hide-offset = <0x3e8>;
			default-on;
		};

		vdd18 {
			regulator-name = "vdd18";
			reg = <0x40038810 0x02 0x4003883c 0x7f00 0x400388c0 0x400>;
			regulator-cal-channel = <0x40038844 0x01 0x15>;
			regulator-default-microvolt = <0x1b7740>;
			regulator-step-microvolt = <0x186a>;
			regulator-min-microvolt = <0x118c30>;
			regulator-max-microvolt = <0x1dc130>;
			regulator-microvolt-offset = <0x00>;
			hide-offset = <0x3e8>;
			default-on;
		};

		vddwifipa {
			regulator-name = "vddwifipa";
			reg = <0x40038814 0x800 0x40038818 0xff 0x00 0x00>;
			regulator-cal-channel = <0x40038844 0x20 0x17>;
			regulator-default-microvolt = <0x1b7740>;
			regulator-step-microvolt = <0x2710>;
			regulator-min-microvolt = <0x124f80>;
			regulator-max-microvolt = <0x395f80>;
			regulator-microvolt-offset = <0x00>;
			hide-offset = <0x3e8>;
		};

		vddsdcore {
			regulator-name = "vddsdcore";
			reg = <0x40038814 0x400 0x40038830 0xff00 0x00 0x00>;
			regulator-cal-channel = <0x40038844 0xa0 0x17>;
			regulator-default-microvolt = <0x2dc6c0>;
			regulator-step-microvolt = <0x2710>;
			regulator-min-microvolt = <0x124f80>;
			regulator-max-microvolt = <0x395f80>;
			regulator-microvolt-offset = <0x00>;
			hide-offset = <0x3e8>;
		};

		vddsdio {
			regulator-name = "vddsdio";
			reg = <0x40038814 0x01 0x40038828 0xff 0x00 0x00>;
			regulator-cal-channel = <0x40038844 0x08 0x1d>;
			regulator-default-microvolt = <0x2dc6c0>;
			regulator-step-microvolt = <0x2710>;
			regulator-min-microvolt = <0x124f80>;
			regulator-max-microvolt = <0x395f80>;
			regulator-microvolt-offset = <0x00>;
			hide-offset = <0x3e8>;
		};

		vddsim0 {
			regulator-name = "vddsim0";
			reg = <0x40038814 0x02 0x40038828 0xff00 0x00 0x00>;
			regulator-cal-channel = <0x40038844 0x500 0x16>;
			regulator-default-microvolt = <0x1b7740>;
			regulator-step-microvolt = <0x2710>;
			regulator-min-microvolt = <0x124f80>;
			regulator-max-microvolt = <0x395f80>;
			regulator-microvolt-offset = <0x00>;
			hide-offset = <0x3e8>;
			status = "disabled";
		};

		vddsim1 {
			regulator-name = "vddsim1";
			reg = <0x40038814 0x04 0x4003882c 0xff 0x00 0x00>;
			regulator-cal-channel = <0x40038844 0x400 0x16>;
			regulator-default-microvolt = <0x1b7740>;
			regulator-step-microvolt = <0x2710>;
			regulator-min-microvolt = <0x124f80>;
			regulator-max-microvolt = <0x395f80>;
			regulator-microvolt-offset = <0x00>;
			hide-offset = <0x3e8>;
			status = "disabled";
		};

		vddsim2 {
			regulator-name = "vddsim2";
			reg = <0x40038814 0x08 0x4003882c 0xff00 0x00 0x00>;
			regulator-cal-channel = <0x40038844 0x300 0x16>;
			regulator-default-microvolt = <0x1b7740>;
			regulator-step-microvolt = <0x2710>;
			regulator-min-microvolt = <0x124f80>;
			regulator-max-microvolt = <0x395f80>;
			regulator-microvolt-offset = <0x00>;
			hide-offset = <0x3e8>;
		};

		vddcama {
			regulator-name = "vddcama";
			reg = <0x40038814 0x10 0x40038830 0xff 0x00 0x00>;
			regulator-cal-channel = <0x40038844 0x200 0x16>;
			regulator-default-microvolt = <0x2ab980>;
			regulator-step-microvolt = <0x2710>;
			regulator-min-microvolt = <0x124f80>;
			regulator-max-microvolt = <0x395f80>;
			regulator-microvolt-offset = <0x00>;
			hide-offset = <0x3e8>;
		};

		vddcamd {
			regulator-name = "vddcamd";
			reg = <0x40038814 0x20 0x4003881c 0x7f 0x00 0x00>;
			regulator-cal-channel = <0x40038844 0x02 0x15>;
			regulator-default-microvolt = <0x16e360>;
			regulator-step-microvolt = <0x186a>;
			regulator-min-microvolt = <0x118c30>;
			regulator-max-microvolt = <0x1dc130>;
			regulator-microvolt-offset = <0x00>;
			hide-offset = <0x3e8>;
		};

		vddcamio {
			regulator-name = "vddcamio";
			reg = <0x40038814 0x40 0x4003881c 0x7f00 0x00 0x00>;
			regulator-cal-channel = <0x40038844 0x03 0x15>;
			regulator-default-microvolt = <0x1b7740>;
			regulator-step-microvolt = <0x186a>;
			regulator-min-microvolt = <0x118c30>;
			regulator-max-microvolt = <0x1dc130>;
			regulator-microvolt-offset = <0x00>;
			hide-offset = <0x3e8>;
		};

		vddcammot {
			regulator-name = "vddcammot";
			reg = <0x40038814 0x80 0x40038834 0xff 0x00 0x00>;
			regulator-cal-channel = <0x40038844 0x40 0x17>;
			regulator-default-microvolt = <0x2ab980>;
			regulator-step-microvolt = <0x2710>;
			regulator-min-microvolt = <0x124f80>;
			regulator-max-microvolt = <0x395f80>;
			regulator-microvolt-offset = <0x00>;
			hide-offset = <0x3e8>;
		};

		vddusb {
			regulator-name = "vddusb";
			reg = <0x40038814 0x100 0x4003883c 0xff 0x00 0x00>;
			regulator-cal-channel = <0x40038844 0x10 0x1d>;
			regulator-default-microvolt = <0x325aa0>;
			regulator-step-microvolt = <0x2710>;
			regulator-min-microvolt = <0x124f80>;
			regulator-max-microvolt = <0x395f80>;
			regulator-microvolt-offset = <0x00>;
			hide-offset = <0x3e8>;
			linux,phandle = <0x4a>;
			phandle = <0x4a>;
		};

		vddkpled {
			regulator-name = "vddkpled";
			reg = <0x400388f4 0x100 0x400388f4 0xff 0x00 0x00>;
			regulator-cal-channel = <0x400388f8 0x3000 0x18>;
			regulator-default-microvolt = <0x325aa0>;
			regulator-step-microvolt = <0x2710>;
			regulator-min-microvolt = <0x124f80>;
			regulator-max-microvolt = <0x395f80>;
			regulator-microvolt-offset = <0x00>;
			hide-offset = <0x3e8>;
			linux,phandle = <0x38>;
			phandle = <0x38>;
		};

		vddvibr {
			regulator-name = "vddvibr";
			reg = <0x400388f8 0x100 0x400388f8 0xff 0x00 0x00>;
			regulator-cal-channel = <0x400388f8 0x2000 0x18>;
			regulator-default-microvolt = <0x2dc6c0>;
			regulator-step-microvolt = <0x2710>;
			regulator-min-microvolt = <0x124f80>;
			regulator-max-microvolt = <0x395f80>;
			regulator-microvolt-offset = <0x00>;
			hide-offset = <0x3e8>;
		};
	};

	sprd-audio-devices {
		compatible = "sprd,sound";
		#address-cells = <0x01>;
		#size-cells = <0x01>;

		sprd-codec {
			compatible = "sprd,sprd-codec";
			status = "okay";
			sprd,def_da_fs = <0xac44>;
			sprd,ap_irq = <0xa4>;
			sprd,dp_irq = <0x34>;
			sprd,reg_dp = <0x40000000 0x2000>;
			interrupt-parent = <0x28>;
			interrupts = <0x07 0x00>;
			sprd,audio_power_ver = <0x04>;
			linux,phandle = <0x2b>;
			phandle = <0x2b>;
		};

		sprd-codec-v3 {
			compatible = "sprd,sprd-codec-v3";
			status = "disable";
			sprd,def_da_fs = <0xac44>;
			sprd,ap_irq = <0xa4>;
			sprd,dp_irq = <0x34>;
			sprd,reg_dp = <0x40000000 0x2000>;
			interrupt-parent = <0x28>;
			interrupts = <0x07 0x00>;
			linux,phandle = <0x2d>;
			phandle = <0x2d>;
		};

		sprd-codec-v1 {
			compatible = "sprd,sprd-codec-v1";
			status = "disable";
			sprd,def_da_fs = <0xac44>;
			sprd,ap_irq = <0x67>;
			sprd,dp_irq = <0x3f>;
		};

		null-codec {
			compatible = "sprd,null-codec";
			linux,phandle = <0x30>;
			phandle = <0x30>;
		};

		vbc-r2p0 {
			compatible = "sprd,vbc-r2p0";
			status = "okay";
			sprd,reg_vbc = <0x40020000 0x20000>;
			linux,phandle = <0x2a>;
			phandle = <0x2a>;
		};

		vbc-r1p0 {
			compatible = "sprd,vbc-r1p0";
			status = "disable";
		};

		vaudio {
			compatible = "sprd,vaudio";
			linux,phandle = <0x29>;
			phandle = <0x29>;
		};

		bt-i2s-config {
			sprd,def_pcm_config;
		};

		fm-i2s-config {
		};

		i2s@0 {
			compatible = "sprd,i2s";
			status = "okay";
			sprd,dai_name = "i2s_bt_sco0";
			sprd,id = <0x00>;
			sprd,hw_port = <0x00>;
			sprd,base = <0x70d00000 0x100000>;
			sprd,dma_rx_no = <0x03>;
			sprd,dma_tx_no = <0x04>;
			sprd,config_type = "pcm";
			sprd,slave_timeout = <0xf11>;
			sprd,_hw_port = <0x00>;
			sprd,fs = <0x1f40>;
			sprd,bus_type = <0x01>;
			sprd,rtx_mode = <0x03>;
			sprd,byte_per_chan = <0x01>;
			sprd,slave_mode = <0x00>;
			sprd,lsb = <0x01>;
			sprd,lrck = <0x01>;
			sprd,low_for_left = <0x01>;
			sprd,clk_inv = <0x00>;
			sprd,pcm_short_frame = <0x01>;
			sprd,pcm_slot = <0x01>;
			sprd,pcm_cycle = <0x01>;
			sprd,tx_watermark = <0x0c>;
			sprd,rx_watermark = <0x14>;
			linux,phandle = <0x2e>;
			phandle = <0x2e>;
		};

		i2s@1 {
			compatible = "sprd,i2s";
			status = "okay";
			sprd,dai_name = "i2s_bt_sco1";
			sprd,id = <0x01>;
			sprd,hw_port = <0x01>;
			sprd,base = <0x70e00000 0x100000>;
			sprd,dma_rx_no = <0x05>;
			sprd,dma_tx_no = <0x06>;
			linux,phandle = <0x2f>;
			phandle = <0x2f>;
		};

		i2s@2 {
			compatible = "sprd,i2s";
			status = "disable";
			sprd,dai_name = "i2s_bt_sco2";
			sprd,id = <0x02>;
			sprd,hw_port = <0x02>;
			sprd,base = <0x70f00000 0x100000>;
			sprd,dma_rx_no = <0x07>;
			sprd,dma_tx_no = <0x08>;
		};

		i2s@3 {
			compatible = "sprd,i2s";
			status = "disable";
			sprd,dai_name = "i2s_bt_sco3";
			sprd,id = <0x03>;
			sprd,hw_port = <0x03>;
			sprd,base = <0x71000000 0x100000>;
			sprd,dma_rx_no = <0x09>;
			sprd,dma_tx_no = <0x0a>;
		};

		sprd-pcm-audio {
			compatible = "sprd,sprd-pcm";
			linux,phandle = <0x2c>;
			phandle = <0x2c>;
		};

		sound@0 {
			compatible = "sprd,vbc-r2p0-sprd-codec";
			sprd,model = "sprdphone";
			sprd,vaudio = <0x29>;
			sprd,vbc = <0x2a>;
			sprd,codec = <0x2b>;
			sprd,pcm = <0x2c>;
		};

		sound@1 {
			compatible = "sprd,vbc-r2p0-sprd-codec-v3";
			sprd,model = "sprdphone";
			sprd,vaudio = <0x29>;
			sprd,vbc = <0x2a>;
			sprd,codec = <0x2d>;
			sprd,pcm = <0x2c>;
		};

		sound@2 {
			compatible = "sprd,i2s-null-codec";
			sprd,model = "all-i2s";
			sprd,i2s = <0x2e 0x2f>;
			sprd,codec = <0x30>;
			sprd,pcm = <0x2c>;
		};
	};

	rt9532-charger {
		compatible = "samsung,rt9532-charger";
		chg-float-voltage = <0x10fe>;
		en-set = <0x31 0xa9 0x00>;
		chg-state = <0x31 0xea 0x00>;
		chg-det = <0x31 0xeb 0x00>;
	};

	sec-fuelgauge {
		compatible = "samsung,sec-fuelgauge";
		capacity-max = <0x3e8>;
		capacity-max-margin = <0x3e8>;
		capacity-min = <0x0a>;
		fg-irq-attr = <0x00>;
		fuel-alert-soc = <0x3e8>;
		temp_adc_channel = <0x00>;
		gpios = <0x32 0x00 0x00>;
		vmode = <0x00>;
		alm_soc = <0x05>;
		alm_vbat = <0xdac>;
		soft_vbat_uvlo = <0xc4e>;
		rint = <0x118>;
		cnom = <0x5be>;
		rsense_real = <0xd1>;
		rsense_spec = <0xc8>;
		relax_current = <0x32>;
		cnom_temp_tab = <0x401 0x5be 0x3f2 0x578 0x3e8 0x4b0 0x3de 0x384 0x3d4 0x2ee>;
		rint_temp_tab = <0x401 0x118 0x3f2 0x1ae 0x3e8 0x1f4>;
		ocv_table = <0x10cb 0x64 0x1090 0x5f 0x105a 0x5a 0x1027 0x55 0xff6 0x50 0xfcb 0x4b 0xf93 0x46 0xf78 0x41 0xf53 0x3c 0xf20 0x37 0xf00 0x32 0xeeb 0x2d 0xeda 0x28 0xecc 0x23 0xec3 0x1e 0xebc 0x19 0xeab 0x14 0xe8b 0x0f 0xe6e 0x0a 0xe66 0x05 0xd48 0x00>;

		sprd_fgu {
			compatible = "sprd,sprd_fgu";
			interrupt-parent = <0x28>;
			interrupts = <0x04 0x00>;
		};
	};

	sec-battery {
		compatible = "samsung,sec-battery";
		battery,vendor = "SDI SDI";
		battery,charger_name = "sec-charger";
		battery,fuelgauge_name = "sec-fuelgauge";
		battery,technology = <0x02>;
		battery,chip_vendor = "SPRD";
		battery,temp_adc_type = <0x01>;
		battery,polling_time = <0x0a 0x1e 0x1e 0x1e 0xe10>;
		battery,adc_check_count = <0x05>;
		battery,cable_check_type = <0x04>;
		battery,cable_source_type = <0x03>;
		battery,event_waiting_time = <0x258>;
		battery,polling_type = <0x01>;
		battery,monitor_initial_count = <0x03>;
		battery,battery_check_type = <0x05>;
		battery,check_count = <0x00>;
		battery,check_adc_max = <0x5a0>;
		battery,check_adc_min = <0x00>;
		battery,ovp_uvlo_check_type = <0x03>;
		battery,thermal_source = <0x02>;
		battery,temp_table_adc = <0x12e 0x1a7 0x22a 0x2f9 0x32b 0x355 0x3a1 0x3ce 0x416 0x49b 0x4d0 0x5a6 0x6ad 0x6f3 0x711 0x784 0x7b0 0x834 0x84f 0x8cc 0x8de 0x904 0x941>;
		battery,temp_table_data = <0x384 0x320 0x2bc 0x258 0x23a 0x226 0x1f4 0x1e0 0x1c2 0x190 0x17c 0x12c 0xc8 0xaa 0x96 0x64 0x50 0x14 0x00 0xffffffce 0xffffffba 0xffffff9c 0xffffff38>;
		battery,temp_check_type = <0x02>;
		battery,temp_check_count = <0x01>;
		battery,temp_high_threshold_event = <0x226>;
		battery,temp_high_recovery_event = <0x1f4>;
		battery,temp_low_threshold_event = <0xffffffce>;
		battery,temp_low_recovery_event = <0x00>;
		battery,temp_high_threshold_normal = <0x226>;
		battery,temp_high_recovery_normal = <0x1f4>;
		battery,temp_low_threshold_normal = <0xffffffce>;
		battery,temp_low_recovery_normal = <0x00>;
		battery,temp_high_threshold_lpm = <0x226>;
		battery,temp_high_recovery_lpm = <0x1f4>;
		battery,temp_low_threshold_lpm = <0xffffffce>;
		battery,temp_low_recovery_lpm = <0x00>;
		battery,full_check_type = <0x07>;
		battery,full_check_type_2nd = <0x00>;
		battery,full_check_count = <0x02>;
		battery,chg_gpio_full_check = <0x00>;
		battery,chg_polarity_full_check = <0x01>;
		battery,full_condition_type = <0x0f>;
		battery,full_condition_soc = <0x64>;
		battery,full_condition_vcell = <0x109a>;
		battery,recharge_check_count = <0x03>;
		battery,recharge_condition_type = <0x04>;
		battery,recharge_condition_soc = <0x5f>;
		battery,recharge_condition_vcell = <0x10ae>;
		battery,charging_total_time = <0x5460>;
		battery,recharging_total_time = <0x1518>;
		battery,charging_reset_time = <0x00>;
		battery,chg_irq_attr = <0x03>;
		battery,always_enable;
		battery,swelling_high_temp_block = <0x1c2>;
		battery,swelling_high_temp_recov = <0x190>;
		battery,swelling_low_temp_block = <0x64>;
		battery,swelling_low_temp_recov = <0x96>;
		battery,swelling_high_chg_current = <0x2bc>;
		battery,swelling_low_chg_current = <0x2bc>;
		battery,swelling_full_check_current_2nd = <0x00>;
		battery,swelling_drop_float_voltage = <0x1068>;
		battery,swelling_high_rechg_voltage = <0x1018>;
		battery,swelling_low_rechg_voltage = <0xfb4>;
		battery,swelling_block_time = <0x258>;
		battery,chg_float_voltage = <0x10fe>;
		battery,input_current_limit = <0x2bc 0x1cc 0x1cc 0x2bc 0x1cc 0x2bc 0x2bc 0x1cc 0x1cc 0x2bc 0x2bc 0x2bc 0x2bc 0x1cc 0x2bc 0x12c 0x2bc 0x2bc 0x12c 0x2bc 0x2bc 0x1cc 0x1cc>;
		battery,fast_charging_current = <0x3cf 0x00 0x3cf 0x3cf 0x3cf 0x3cf 0x3cf 0x3cf 0x00 0x3cf 0x3cf 0x3cf 0x3cf 0xffffffff 0x3cf 0x3cf 0x3cf 0x3cf 0x3cf 0x3cf 0x3cf 0x00 0x00>;
		battery,full_check_current_1st = <0xaf 0x00 0xaf 0xaf 0xaf 0xaf 0xaf 0xaf 0x00 0xaf 0xaf 0xaf 0xaf 0x00 0xaf 0xaf 0xaf 0xaf 0xaf 0xaf 0xaf 0x00 0x00>;
		battery,full_check_current_2nd = <0x708 0x00 0x708 0x708 0x708 0x708 0x708 0x708 0x00 0x708 0x708 0x708 0x708 0x00 0x708 0x708 0x708 0x708 0x708 0x708 0x708 0x00 0x00>;
	};

	cpus {
		#address-cells = <0x01>;
		#size-cells = <0x00>;

		cpu@f00 {
			device_type = "cpu";
			compatible = "arm,cortex-a7";
			reg = <0xf00>;
		};

		cpu@f01 {
			device_type = "cpu";
			compatible = "arm,cortex-a7";
			reg = <0xf01>;
		};

		cpu@f02 {
			device_type = "cpu";
			compatible = "arm,cortex-a7";
			reg = <0xf02>;
		};

		cpu@f03 {
			device_type = "cpu";
			compatible = "arm,cortex-a7";
			reg = <0xf03>;
		};
	};

	pmu {
		compatible = "arm,cortex-a7-pmu";
		interrupts = <0x00 0x5c 0x00 0x00 0x5d 0x00 0x00 0x5e 0x00 0x00 0x5f 0x00>;
	};

	sec-debug {

		crash_key {
			keys = "vol-down\0power\0power";
			size-keys = <0x03>;
			timeout = <0x3e8>;
		};
	};

	interrupt-controller@12001000 {
		compatible = "arm,cortex-a15-gic\0arm,cortex-a9-gic";
		#interrupt-cells = <0x03>;
		#address-cells = <0x00>;
		interrupt-controller;
		reg = <0x12001000 0x1000 0x12002000 0x1000>;
		linux,phandle = <0x01>;
		phandle = <0x01>;
	};

	uart@70000000 {
		compatible = "sprd,serial";
		interrupts = <0x00 0x02 0x00>;
		reg = <0x70000000 0x1000>;
		clock-names = "clk_uart0";
		clocks = <0x33 0x3c>;
		sprdclk = <0x2dc6c00>;
		sprdwaketype = "BT_RTS_HIGH_WHEN_SLEEP";
	};

	uart@70100000 {
		compatible = "sprd,serial";
		interrupts = <0x00 0x03 0x00>;
		reg = <0x70100000 0x1000>;
		clock-names = "clk_uart1";
		clocks = <0x33 0x3d>;
		sprdclk = <0x18cba80>;
		sprdwaketype = "BT_RTS_HIGH_WHEN_SLEEP";
	};

	uart@70200000 {
		compatible = "sprd,serial";
		interrupts = <0x00 0x04 0x00>;
		reg = <0x70200000 0x1000>;
		clock-names = "clk_uart2";
		clocks = <0x33 0x3e>;
		sprdclk = <0x18cba80>;
		sprdwaketype = "BT_RTS_HIGH_WHEN_SLEEP";
	};

	timer {
		compatible = "sprd,scx35-timer";
		reg = <0x40230000 0x1000 0x40050000 0x1000 0x40220000 0x1000 0x40330000 0x1000 0x40340000 0x1000>;
		interrupts = <0x00 0x76 0x00 0x00 0x1c 0x00 0x00 0x1d 0x00 0x00 0x77 0x00 0x00 0x79 0x00 0x00 0x1f 0x00>;
	};

	clockdevice {
		compatible = "sprd,scx35-clock";
		#clock-cells = <0x01>;
		linux,phandle = <0x33>;
		phandle = <0x33>;
	};

	gpio@40210000 {
		compatible = "sprd,d-eic-gpio";
		reg = <0x40210000 0x1000>;
		gpio-controller;
		interrupt-controller;
		#interrupt-cells = <0x02>;
		#gpio-cells = <0x02>;
		gpiobase = <0x120>;
		ngpios = <0x10>;
		interrupts = <0x00 0x25 0x00>;
	};

	gpio@40280000 {
		compatible = "sprd,d-gpio-gpio";
		reg = <0x40280000 0x1000>;
		gpio-controller;
		interrupt-controller;
		#interrupt-cells = <0x02>;
		#gpio-cells = <0x02>;
		gpiobase = <0x00>;
		ngpios = <0x100>;
		interrupts = <0x00 0x23 0x00>;
		linux,phandle = <0x31>;
		phandle = <0x31>;
	};

	sprd_fm@40270000 {
		compatible = "sprd,sprd_fm";
		reg = <0x40270000 0x1000>;
	};

	pinctrl {
		compatible = "sprd,pinctrl";
		reg = <0x402a0000 0x1000>;
		pwr_domain = "vddsdio\0vddsim0\0vddsim1\0vddsim2\0vdd28";
		ctrl_desc = <0x10 0x10 0x01 0x10 0x11 0x01 0x10 0x12 0x01 0x10 0x13 0x01 0x10 0x14 0x01>;
	};

	adic {
		compatible = "sprd,adi";
		reg = <0x40030000 0x10000>;
	};

	adi_bus {
		compatible = "sprd,adi-bus";
		interrupts = <0x00 0x26 0x00>;
		reg = <0x40038000 0x1000>;
		interrupt-controller;
		sprd,irqnums = <0x0b>;
		#interrupt-cells = <0x02>;
		#address-cells = <0x01>;
		#size-cells = <0x01>;
		ranges = <0x40 0x40038040 0x40 0x80 0x40038080 0x80 0x100 0x40038100 0x80 0x480 0x40038480 0x80>;
		linux,phandle = <0x28>;
		phandle = <0x28>;

		headset_sprd_sc2723 {
			compatible = "sprd,headset_sprd_sc2723";
			gpio_switch = <0x00>;
			gpio_detect = <0x138>;
			gpio_button = <0x133>;
			irq_trigger_level_detect = <0x01>;
			irq_trigger_level_button = <0x01>;
			adc_threshold_gnd_average = <0x190>;
			adc_threshold_left_average = <0x1f4>;
			adc_threshold_3pole_detect = <0xcad>;
			adc_threshold_4pole_detect = <0xcae>;
			irq_threshold_buttont = <0x04>;
			voltage_headmicbias = <0x2dc6c0>;
			nbuttons = <0x04>;

			headset_buttons_media {
				adc_min = <0x00>;
				adc_max = <0x1df>;
				code = <0xe2>;
				type = <0x00>;
			};

			headset_buttons_voc_assist {
				adc_min = <0x1e0>;
				adc_max = <0x29a>;
				code = <0x246>;
				type = <0x00>;
			};

			headset_buttons_up {
				adc_min = <0x29b>;
				adc_max = <0x488>;
				code = <0x73>;
				type = <0x00>;
			};

			headset_buttons_down {
				adc_min = <0x489>;
				adc_max = <0xbb8>;
				code = <0x72>;
				type = <0x00>;
			};
		};

		keyboard_backlight {
			compatible = "sprd,keyboard-backlight";
		};

		watchdog@40 {
			compatible = "sprd,watchdog";
			reg = <0x40 0x40>;
			interrupts = <0x03 0x00>;
		};

		rtc@80 {
			compatible = "sprd,rtc";
			reg = <0x80 0x80>;
			interrupts = <0x02 0x00>;
		};

		gpio@100 {
			compatible = "sprd,a-eic-gpio";
			reg = <0x100 0x80>;
			gpio-controller;
			interrupt-controller;
			#interrupt-cells = <0x02>;
			#gpio-cells = <0x02>;
			gpiobase = <0x130>;
			ngpios = <0x10>;
			interrupt-parent = <0x28>;
			interrupts = <0x05 0x00>;
			linux,phandle = <0x32>;
			phandle = <0x32>;
		};

		gpio@480 {
			compatible = "sprd,a-gpio-gpio";
			reg = <0x480 0x80>;
			gpio-controller;
			interrupt-controller;
			#interrupt-cells = <0x02>;
			#gpio-cells = <0x02>;
			gpiobase = <0x100>;
			ngpios = <0x20>;
			interrupt-parent = <0x28>;
			interrupts = <0x01 0x00>;
		};
	};

	keypad@40250000 {
		compatible = "sprd,sci-keypad";
		reg = <0x40250000 0x1000>;
		ngpios = <0x02>;
		gpios = <0x32 0x02 0x00 0x32 0x0a 0x00>;
		interrupts = <0x00 0x24 0x00>;
		sprd,keypad-num-rows = <0x01>;
		sprd,keypad-num-columns = <0x03>;
		sprd,keypad-rows-choose-hw = <0x10000>;
		sprd,keypad-cols-choose-hw = <0x700>;
		sprd,debounce_time = <0x1388>;
		linux,keypad-no-autorepeat;
		sprd,support_long_key;

		key_volume_up {
			keypad,row = <0x00>;
			keypad,column = <0x00>;
			linux,code = <0x73>;
		};

		key_volume_up1 {
			keypad,row = <0x00>;
			keypad,column = <0x02>;
			linux,code = <0x73>;
		};

		key_home {
			keypad,row = <0x00>;
			keypad,column = <0x01>;
			linux,code = <0xac>;
		};
	};

	sec_thermistor {
		compatible = "sec,thermistor";
	};

	ktd2801-bl {
		compatible = "kinetic,backlight-ktd2801";
		backlight-name = "panel";
		backlight-brt-range = <0x00 0x00 0x03 0x06 0x05 0x08 0x66 0x5f 0xff 0xd7>;
		gen-panel-outdoor-mode-en;
		backlight-brt-outdoor = <0xff 0xff>;
		bl-ctrl = <0x31 0xd6 0x00>;
		backlight-on-delay = <0x6e>;
		linux,phandle = <0x34>;
		phandle = <0x34>;
	};

	panel {
		compatible = "sprd,sprdfb-dsi-panel";
		pinctrl-names = "default";
		gen-panel-backlight = <0x34>;
		gen-panel = <0x35>;
		interrupt-parent = <0x31>;
		interrupts = <0x96 0x01>;
		gen-panel-esd-en;
		gen-panel-esd-gpio = <0x31 0x96 0x00>;
		gen-panel-esd-type = <0x01>;

		panel-ext-pin {
			panel-ext-pin-on-0 = <0x36 0x00 0x14 0x37 0x01 0x9c40>;
			panel-ext-pin-on = <0x36 0x01 0x1d4c0>;
			panel-ext-pin-off = <0x36 0x00 0x14 0x37 0x00 0x0a>;

			panel-ext-pin-0 {
				pin-name = "vddkpled";
				pin-type = <0x01>;
				pin-supply = <0x38>;
				linux,phandle = <0x37>;
				phandle = <0x37>;
			};

			panel-ext-pin-1 {
				pin-name = "lcd_rst_n";
				pin-type = <0x00>;
				pin-gpio = <0x31 0x67 0x00>;
				linux,phandle = <0x36>;
				phandle = <0x36>;
			};
		};

		gen-panel {
			linux,phandle = <0x35>;
			phandle = <0x35>;

			gen-panel-st7701-video {
				gen-panel-manu = "SKY";
				gen-panel-name = "st7701";
				gen-panel-id = <0x6c060>;
				gen-panel-dev-id = <0x00>;
				gen-panel-type = <0x02>;
				gen-panel-refresh = <0x3c>;
				gen-panel-xres = <0x1e0>;
				gen-panel-yres = <0x320>;
				gen-panel-width = <0x38>;
				gen-panel-height = <0x5e>;
				gen-panel-work-mode = <0x01>;
				gen-panel-direction = <0x00>;
				gen-panel-suspend-mode = <0x01>;
				gen-panel-bus-width = <0x18>;
				gen-panel-lanes = <0x02>;
				gen-panel-phy-feq = <0x6fd10>;
				gen-panel-h-sync-pol = <0x00>;
				gen-panel-v-sync-pol = <0x00>;
				gen-panel-de-pol = <0x00>;
				gen-panel-te-pol = <0x00>;
				gen-panel-color-mode-pol = <0x01>;
				gen-panel-shut-down-pol = <0x01>;
				gen-panel-h-front-porch = <0xdc>;
				gen-panel-h-back-porch = <0x6e>;
				gen-panel-h-sync-width = <0x32>;
				gen-panel-v-front-porch = <0x07>;
				gen-panel-v-back-porch = <0x05>;
				gen-panel-v-sync-width = <0x05>;
				gen-panel-pkt-dinfo-addr-offset = <0x00>;
				gen-panel-pkt-dinfo-addr-length = <0x01>;
				gen-panel-pkt-dinfo-data-offset = <0x01>;
				gen-panel-pkt-dinfo-data-length = <0x01>;
				gen-panel-init-cmds = [05 00 00 78 00 01 01 39 00 00 00 00 06 ff 77 01 00 00 11 15 00 00 00 00 02 d1 11 05 00 00 78 00 01 11 39 00 00 00 00 06 ff 77 01 00 00 10 39 00 00 00 00 03 c0 63 00 39 00 00 00 00 03 c1 09 02 39 00 00 00 00 03 c2 37 00 15 00 00 00 00 02 c7 04 15 00 00 00 00 02 cb 12 39 00 00 00 00 11 b0 00 02 86 0f 15 0a 03 09 09 19 08 15 12 89 0d d7 39 00 00 00 00 11 b1 00 01 87 0f 14 08 02 09 09 1b 09 18 14 8f 14 d7 39 00 00 00 00 06 ff 77 01 00 00 11 15 00 00 00 00 02 b0 5f 15 00 00 00 00 02 b1 4b 15 00 00 00 00 02 b2 07 15 00 00 00 00 02 b3 80 15 00 00 00 00 02 b5 47 15 00 00 00 00 02 b7 8a 15 00 00 00 00 02 b8 20 15 00 00 00 00 02 b9 11 15 00 00 00 00 02 ba 00 15 00 00 00 00 02 bb 00 15 00 00 00 00 02 bc 00 15 00 00 00 00 02 c0 03 15 00 00 00 00 02 c1 78 15 00 00 00 00 02 c2 78 15 00 00 00 00 02 d0 88 39 00 00 00 00 04 e0 00 00 02 39 00 00 00 00 0c e1 03 00 00 00 02 00 00 00 00 60 60 39 00 00 00 00 0e e2 30 30 40 40 29 00 00 00 28 00 00 00 00 39 00 00 00 00 05 e3 00 00 33 33 39 00 00 00 00 03 e4 44 44 39 00 00 00 00 11 e5 06 30 3c a0 08 30 3c a0 0a 30 3c a0 0c 30 3c a0 39 00 00 00 00 05 e6 00 00 33 33 39 00 00 00 00 03 e7 44 44 39 00 00 00 00 11 e8 05 30 3c a0 07 30 3c a0 09 30 3c a0 0b 30 3c a0 39 00 00 00 00 08 eb 02 01 e4 e4 88 00 00 39 00 00 00 00 11 ed fa b0 2f f4 65 7f ff ff ff ff f7 56 4f f2 0b af 39 00 00 00 00 06 ff 77 01 00 00 13 15 00 00 00 00 03 e6 10 40 15 00 00 00 00 02 36 10 39 00 00 78 00 06 ff 77 01 00 00 00];
				gen-panel-enable-cmds = [05 00 00 64 00 01 29];
				gen-panel-disable-cmds = [05 00 00 64 00 01 28 05 00 00 00 00 01 10];
				gen-panel-read-id = [da 00 01 db 00 01 dc 00 01];
				gen-panel-read-status-reg = [0a];
				gen-panel-read-status-ok = [9a];
				status = "okay";
			};

			gen-panel-s6d77a1a01-video {
				gen-panel-manu = "BOE";
				gen-panel-name = "s6d77a1a01";
				gen-panel-id = <0x66108>;
				gen-panel-dev-id = <0x00>;
				gen-panel-type = <0x02>;
				gen-panel-refresh = <0x3c>;
				gen-panel-xres = <0x1e0>;
				gen-panel-yres = <0x320>;
				gen-panel-width = <0x38>;
				gen-panel-height = <0x5e>;
				gen-panel-work-mode = <0x01>;
				gen-panel-direction = <0x00>;
				gen-panel-suspend-mode = <0x01>;
				gen-panel-bus-width = <0x18>;
				gen-panel-lanes = <0x02>;
				gen-panel-phy-feq = <0x6fd10>;
				gen-panel-h-sync-pol = <0x00>;
				gen-panel-v-sync-pol = <0x00>;
				gen-panel-de-pol = <0x00>;
				gen-panel-te-pol = <0x00>;
				gen-panel-color-mode-pol = <0x01>;
				gen-panel-shut-down-pol = <0x01>;
				gen-panel-h-front-porch = <0x84>;
				gen-panel-h-back-porch = <0x78>;
				gen-panel-h-sync-width = <0x20>;
				gen-panel-v-front-porch = <0x0a>;
				gen-panel-v-back-porch = <0x12>;
				gen-panel-v-sync-width = <0x04>;
				gen-panel-pkt-dinfo-addr-offset = <0x00>;
				gen-panel-pkt-dinfo-addr-length = <0x01>;
				gen-panel-pkt-dinfo-data-offset = <0x01>;
				gen-panel-pkt-dinfo-data-length = <0x01>;
				gen-panel-init-cmds = [39 00 00 00 00 03 f0 5a 5a 39 00 00 00 00 03 fc a5 a5 39 00 00 00 00 02 e2 fd 39 00 00 00 00 08 f2 11 04 08 16 0a 98 84 39 00 00 00 00 06 f3 11 00 00 00 10 39 00 00 00 00 2c f4 03 03 23 24 25 25 26 26 29 29 2c 2b 2c 07 08 05 04 04 01 01 22 0a 17 0f 11 23 0d 0a 0b 02 19 13 1e 1f 23 20 05 16 1a 16 1e 24 1e 39 00 00 00 00 1d f5 28 28 b9 21 35 55 06 0a 00 39 00 04 09 49 c6 c9 49 0f 0f 1f 00 10 e0 e2 0e 34 34 03 39 00 00 00 00 08 fd 00 10 11 20 21 1f cc 39 00 00 00 00 12 fe 00 02 01 39 60 40 21 00 4b 00 00 00 f0 00 00 00 0a 39 00 00 00 00 0b ee 04 e3 04 e3 10 00 00 00 00 00 39 00 00 00 00 15 ef 23 01 00 00 2a 49 08 27 21 40 10 24 02 21 21 03 03 40 00 20 39 00 00 00 00 1f f7 02 1a 1b 02 02 0d 0d 09 09 0c 0c 08 08 04 06 02 1a 1b 02 02 0f 0f 0b 0b 0e 0e 0a 0a 05 07 39 00 00 00 00 07 f6 63 21 15 00 00 30 15 00 00 00 00 02 36 10 39 00 00 00 00 34 fa 11 33 14 1a 1b 1f 23 24 24 26 24 1b 19 13 0d 04 08 11 33 14 1a 1b 1f 23 24 23 26 24 1b 19 13 0d 05 08 11 33 14 1a 1b 1f 22 1f 21 25 24 1b 19 13 0d 04 08 39 00 00 00 00 34 fb 11 33 14 1a 1b 1f 23 24 26 28 24 1b 18 13 0d 05 09 11 33 14 1a 1b 1f 23 24 25 28 24 1b 18 13 0d 06 08 11 33 14 1a 1b 1f 22 20 22 27 24 1b 18 13 0d 05 09 39 00 00 00 00 03 fc 5a 5a];
				gen-panel-enable-cmds = [05 00 00 78 00 01 11 05 00 00 14 00 01 29];
				gen-panel-disable-cmds = [05 00 00 32 00 01 28 05 00 00 78 00 01 10];
				gen-panel-read-id = [da 00 01 db 00 01 dc 00 01];
				gen-panel-read-status-reg = [0a];
				gen-panel-read-status-ok = [9a];
				status = "okay";
				gen-panel-mdnie-color-adjustment-mode-cmds = [39 00 00 00 00 09 c2 01 07 32 00 01 e0 03 20 39 00 00 00 00 12 c3 00 00 00 00 00 00 00 00 00 00 00 00 00 00 00 00 00 39 00 00 00 00 07 c4 00 ff ff 00 ff 00 39 00 00 00 00 07 c5 ff 00 00 ff ff 00 39 00 00 00 00 07 c6 ff 00 ff 00 00 ff 39 00 00 00 00 07 c7 ff 00 ff 00 ff 00 39 00 00 00 00 0d c8 00 20 00 20 00 20 00 20 00 20 00 20 39 00 00 00 00 0d c9 00 20 00 20 00 20 00 20 00 20 00 20 39 00 00 00 00 0d ca 00 20 00 20 00 20 00 20 00 20 00 20 39 00 00 00 00 0d cb 00 20 00 20 00 20 00 20 00 20 00 ff 39 00 00 00 00 07 cc 04 00 00 00 00 00 39 00 00 00 00 07 ce 00 00 04 00 00 00 39 00 00 00 00 07 cf 00 00 00 00 04 00 39 00 00 00 00 09 c2 01 00 32 00 01 e0 03 20];
				gen-panel-mdnie-negative-mode-cmds = [39 00 00 00 00 09 c2 01 07 32 00 01 e0 03 20 39 00 00 00 00 12 c3 00 00 00 00 00 00 00 00 00 00 00 00 00 00 00 00 00 39 00 00 00 00 07 c4 ff 00 00 ff 00 ff 39 00 00 00 00 07 c5 00 ff ff 00 00 ff 39 00 00 00 00 07 c6 00 ff 00 ff ff 00 39 00 00 00 00 07 c7 00 ff 00 ff 00 ff 39 00 00 00 00 0d c8 00 20 00 20 00 20 00 20 00 20 00 20 39 00 00 00 00 0d c9 00 20 00 20 00 20 00 20 00 20 00 20 39 00 00 00 00 0d ca 00 20 00 20 00 20 00 20 00 20 00 20 39 00 00 00 00 0d cb 00 20 00 20 00 20 00 20 00 20 00 ff 39 00 00 00 00 07 cc 04 00 00 00 00 00 39 00 00 00 00 07 ce 00 00 04 00 00 00 39 00 00 00 00 07 cf 00 00 00 00 04 00 39 00 00 00 00 09 c2 01 00 32 00 01 e0 03 20];
				gen-panel-mdnie-gray-scale-cmds = [39 00 00 00 00 09 c2 01 07 32 00 01 e0 03 20 39 00 00 00 00 12 c3 00 00 00 00 00 00 00 00 00 00 00 00 00 00 00 00 00 39 00 00 00 00 07 c4 b3 4c b3 4c b3 4c 39 00 00 00 00 07 c5 69 96 69 96 69 96 39 00 00 00 00 07 c6 e2 1d e2 1d e2 1d 39 00 00 00 00 07 c7 ff 00 ff 00 ff 00 39 00 00 00 00 0d c8 00 20 00 20 00 20 00 20 00 20 00 20 39 00 00 00 00 0d c9 00 20 00 20 00 20 00 20 00 20 00 20 39 00 00 00 00 0d ca 00 20 00 20 00 20 00 20 00 20 00 20 39 00 00 00 00 0d cb 00 20 00 20 00 20 00 20 00 20 00 ff 39 00 00 00 00 07 cc 04 00 00 00 00 00 39 00 00 00 00 07 ce 00 00 04 00 00 00 39 00 00 00 00 07 cf 00 00 00 00 04 00 39 00 00 00 00 09 c2 01 00 32 00 01 e0 03 20];
				gen-panel-mdnie-gray-scale-negative-cmds = [39 00 00 00 00 09 c2 01 07 32 00 01 e0 03 20 39 00 00 00 00 12 c3 00 00 00 00 00 00 00 00 00 00 00 00 00 00 00 00 00 39 00 00 00 00 07 c4 4c b3 4c b3 4c b3 39 00 00 00 00 07 c5 96 69 96 69 96 69 39 00 00 00 00 07 c6 1d e2 1d e2 1d e2 39 00 00 00 00 07 c7 00 ff 00 ff 00 ff 39 00 00 00 00 0d c8 00 20 00 20 00 20 00 20 00 20 00 20 39 00 00 00 00 0d c9 00 20 00 20 00 20 00 20 00 20 00 20 39 00 00 00 00 0d ca 00 20 00 20 00 20 00 20 00 20 00 20 39 00 00 00 00 0d cb 00 20 00 20 00 20 00 20 00 20 00 ff 39 00 00 00 00 07 cc 04 00 00 00 00 00 39 00 00 00 00 07 ce 00 00 04 00 00 00 39 00 00 00 00 07 cf 00 00 00 00 04 00 39 00 00 00 00 09 c2 01 00 32 00 01 e0 03 20];
				gen-panel-mdnie-dark-screene-mode-cmds = [39 00 00 00 00 09 c2 01 07 32 00 01 e0 03 20 39 00 00 00 00 12 c3 00 00 00 00 00 00 00 00 00 00 00 00 00 00 00 00 00 39 00 00 00 00 07 c4 ff ff ff ff ff ff 39 00 00 00 00 07 c5 ff ff ff ff ff ff 39 00 00 00 00 07 c6 ff ff ff ff ff ff 39 00 00 00 00 07 c7 ff ff ff ff ff ff 39 00 00 00 00 0d c8 00 20 00 20 00 20 00 20 00 20 00 20 39 00 00 00 00 0d c9 00 20 00 20 00 20 00 20 00 20 00 20 39 00 00 00 00 0d ca 00 20 00 20 00 20 00 20 00 20 00 20 39 00 00 00 00 0d cb 00 20 00 20 00 20 00 20 00 20 00 ff 39 00 00 00 00 07 cc 04 00 00 00 00 00 39 00 00 00 00 07 ce 00 00 04 00 00 00 39 00 00 00 00 07 cf 00 00 00 00 04 00 39 00 00 00 00 09 c2 01 00 32 00 01 e0 03 20];
				gen-panel-mdnie-outdoor-mode-cmds = [39 00 00 00 00 09 c2 07 07 23 00 01 e0 03 20 39 00 00 00 00 12 c3 00 00 00 00 00 00 00 00 00 00 00 00 00 00 00 00 00 39 00 00 00 00 07 c4 00 ff ff 00 ff 00 39 00 00 00 00 07 c5 ff 00 00 ff ff 00 39 00 00 00 00 07 c6 ff 00 ff 00 00 ff 39 00 00 00 00 07 c7 ff 00 ff 00 ff 00 39 00 00 00 00 0d c8 00 17 00 17 00 17 00 17 00 17 04 9c 39 00 00 00 00 0d c9 04 9c 04 9c 00 18 00 18 00 18 00 18 39 00 00 00 00 0d ca 00 18 00 18 00 18 04 9a 06 9b 06 9b 39 00 00 00 00 0d cb 06 9b 09 9c 1e a0 56 a9 ef be 00 ff 39 00 00 00 00 07 cc 04 8f 1f 88 1f e9 39 00 00 00 00 07 ce 1f c3 04 54 1f e9 39 00 00 00 00 07 cf 1f c3 1f 88 04 b5 39 00 00 00 00 09 c2 07 00 23 00 01 e0 03 20];
				gen-panel-mdnie-ui-mode-cmds = [39 00 00 00 00 09 c2 05 07 23 00 01 e0 03 20 39 00 00 00 00 12 c3 00 00 00 00 00 00 00 00 00 00 00 00 00 00 00 00 00 39 00 00 00 00 07 c4 00 ff ff 00 ff 00 39 00 00 00 00 07 c5 ff 00 00 ff ff 00 39 00 00 00 00 07 c6 ff 00 ff 00 00 ff 39 00 00 00 00 07 c7 ff 00 ff 00 ff 00 39 00 00 00 00 0d c8 00 20 00 20 00 20 00 20 00 20 00 20 39 00 00 00 00 0d c9 00 20 00 20 00 20 00 20 00 20 00 20 39 00 00 00 00 0d ca 00 20 00 20 00 20 00 20 00 20 00 20 39 00 00 00 00 0d cb 00 20 00 20 00 20 00 20 00 20 00 ff 39 00 00 00 00 07 cc 04 8f 1f 88 1f e9 39 00 00 00 00 07 ce 1f c3 04 54 1f e9 39 00 00 00 00 07 cf 1f c3 1f 88 04 b5 39 00 00 00 00 09 c2 05 00 23 00 01 e0 03 20];
				gen-panel-mdnie-video-mode-cmds = [39 00 00 00 00 09 c2 05 07 23 00 01 e0 03 20 39 00 00 00 00 12 c3 00 00 00 00 00 00 00 00 00 00 00 00 00 00 00 00 00 39 00 00 00 00 07 c4 00 ff ff 00 ff 00 39 00 00 00 00 07 c5 ff 00 00 ff ff 00 39 00 00 00 00 07 c6 ff 00 ff 00 00 ff 39 00 00 00 00 07 c7 ff 00 ff 00 ff 00 39 00 00 00 00 0d c8 00 20 00 20 00 20 00 20 00 20 00 20 39 00 00 00 00 0d c9 00 20 00 20 00 20 00 20 00 20 00 20 39 00 00 00 00 0d ca 00 20 00 20 00 20 00 20 00 20 00 20 39 00 00 00 00 0d cb 00 20 00 20 00 20 00 20 00 20 00 ff 39 00 00 00 00 07 cc 04 8f 1f 88 1f e9 39 00 00 00 00 07 ce 1f c3 04 54 1f e9 39 00 00 00 00 07 cf 1f c3 1f 88 04 b5 39 00 00 00 00 09 c2 05 00 23 00 01 e0 03 20];
				gen-panel-mdnie-camera-mode-cmds = [39 00 00 00 00 09 c2 05 07 23 00 01 e0 03 20 39 00 00 00 00 12 c3 00 00 00 00 00 00 00 00 00 00 00 00 00 00 00 00 00 39 00 00 00 00 07 c4 00 ff ff 00 ff 00 39 00 00 00 00 07 c5 ff 00 00 ff ff 00 39 00 00 00 00 07 c6 ff 00 ff 00 00 ff 39 00 00 00 00 07 c7 ff 00 ff 00 ff 00 39 00 00 00 00 0d c8 00 20 00 20 00 20 00 20 00 20 00 20 39 00 00 00 00 0d c9 00 20 00 20 00 20 00 20 00 20 00 20 39 00 00 00 00 0d ca 00 20 00 20 00 20 00 20 00 20 00 20 39 00 00 00 00 0d cb 00 20 00 20 00 20 00 20 00 20 00 ff 39 00 00 00 00 07 cc 04 8f 1f 88 1f e9 39 00 00 00 00 07 ce 1f c3 04 54 1f e9 39 00 00 00 00 07 cf 1f c3 1f 88 04 b5 39 00 00 00 00 09 c2 05 00 23 00 01 e0 03 20];
				gen-panel-mdnie-gallery-mode-cmds = [39 00 00 00 00 09 c2 05 07 23 00 01 e0 03 20 39 00 00 00 00 12 c3 00 00 00 00 00 00 00 00 00 00 00 00 00 00 00 00 00 39 00 00 00 00 07 c4 00 ff ff 00 ff 00 39 00 00 00 00 07 c5 ff 00 00 ff ff 00 39 00 00 00 00 07 c6 ff 00 ff 00 00 ff 39 00 00 00 00 07 c7 ff 00 ff 00 ff 00 39 00 00 00 00 0d c8 00 20 00 20 00 20 00 20 00 20 00 20 39 00 00 00 00 0d c9 00 20 00 20 00 20 00 20 00 20 00 20 39 00 00 00 00 0d ca 00 20 00 20 00 20 00 20 00 20 00 20 39 00 00 00 00 0d cb 00 20 00 20 00 20 00 20 00 20 00 ff 39 00 00 00 00 07 cc 04 8f 1f 88 1f e9 39 00 00 00 00 07 ce 1f c3 04 54 1f e9 39 00 00 00 00 07 cf 1f c3 1f 88 04 b5 39 00 00 00 00 09 c2 05 00 23 00 01 e0 03 20];
				gen-panel-mdnie-vt-mode-cmds = [39 00 00 00 00 09 c2 05 07 23 00 01 e0 03 20 39 00 00 00 00 12 c3 00 00 00 00 00 00 00 00 00 00 00 00 00 00 00 00 00 39 00 00 00 00 07 c4 00 ff ff 00 ff 00 39 00 00 00 00 07 c5 ff 00 00 ff ff 00 39 00 00 00 00 07 c6 ff 00 ff 00 00 ff 39 00 00 00 00 07 c7 ff 00 ff 00 ff 00 39 00 00 00 00 0d c8 00 20 00 20 00 20 00 20 00 20 00 20 39 00 00 00 00 0d c9 00 20 00 20 00 20 00 20 00 20 00 20 39 00 00 00 00 0d ca 00 20 00 20 00 20 00 20 00 20 00 20 39 00 00 00 00 0d cb 00 20 00 20 00 20 00 20 00 20 00 ff 39 00 00 00 00 07 cc 04 8f 1f 88 1f e9 39 00 00 00 00 07 ce 1f c3 04 54 1f e9 39 00 00 00 00 07 cf 1f c3 1f 88 04 b5 39 00 00 00 00 09 c2 05 00 23 00 01 e0 03 20];
				gen-panel-mdnie-browser-mode-cmds = [39 00 00 00 00 09 c2 05 07 23 00 01 e0 03 20 39 00 00 00 00 12 c3 00 00 00 00 00 00 00 00 00 00 00 00 00 00 00 00 00 39 00 00 00 00 07 c4 00 ff ff 00 ff 00 39 00 00 00 00 07 c5 ff 00 00 ff ff 00 39 00 00 00 00 07 c6 ff 00 ff 00 00 ff 39 00 00 00 00 07 c7 ff 00 ff 00 ff 00 39 00 00 00 00 0d c8 00 20 00 20 00 20 00 20 00 20 00 20 39 00 00 00 00 0d c9 00 20 00 20 00 20 00 20 00 20 00 20 39 00 00 00 00 0d ca 00 20 00 20 00 20 00 20 00 20 00 20 39 00 00 00 00 0d cb 00 20 00 20 00 20 00 20 00 20 00 ff 39 00 00 00 00 07 cc 04 8f 1f 88 1f e9 39 00 00 00 00 07 ce 1f c3 04 54 1f e9 39 00 00 00 00 07 cf 1f c3 1f 88 04 b5 39 00 00 00 00 09 c2 05 00 23 00 01 e0 03 20];
				gen-panel-mdnie-ebook-mode-cmds = [39 00 00 00 00 09 c2 05 07 23 00 01 e0 03 20 39 00 00 00 00 12 c3 00 00 00 00 00 00 00 00 00 00 00 00 00 00 00 00 00 39 00 00 00 00 07 c4 00 ff ff 00 ff 00 39 00 00 00 00 07 c5 ff 00 00 ff ff 00 39 00 00 00 00 07 c6 ff 00 ff 00 00 ff 39 00 00 00 00 07 c7 ff 00 ff 00 ff 00 39 00 00 00 00 0d c8 00 20 00 20 00 20 00 20 00 20 00 20 39 00 00 00 00 0d c9 00 20 00 20 00 20 00 20 00 20 00 20 39 00 00 00 00 0d ca 00 20 00 20 00 20 00 20 00 20 00 20 39 00 00 00 00 0d cb 00 20 00 20 00 20 00 20 00 20 00 ff 39 00 00 00 00 07 cc 04 8f 1f 88 1f e9 39 00 00 00 00 07 ce 1f c3 04 54 1f e9 39 00 00 00 00 07 cf 1f c3 1f 88 04 b5 39 00 00 00 00 09 c2 05 00 23 00 01 e0 03 20];
				gen-panel-mdnie-email-mode-cmds = [39 00 00 00 00 09 c2 05 07 23 00 01 e0 03 20 39 00 00 00 00 12 c3 00 00 00 00 00 00 00 00 00 00 00 00 00 00 00 00 00 39 00 00 00 00 07 c4 00 ff ff 00 ff 00 39 00 00 00 00 07 c5 ff 00 00 ff ff 00 39 00 00 00 00 07 c6 ff 00 ff 00 00 ff 39 00 00 00 00 07 c7 ff 00 ff 00 ff 00 39 00 00 00 00 0d c8 00 20 00 20 00 20 00 20 00 20 00 20 39 00 00 00 00 0d c9 00 20 00 20 00 20 00 20 00 20 00 20 39 00 00 00 00 0d ca 00 20 00 20 00 20 00 20 00 20 00 20 39 00 00 00 00 0d cb 00 20 00 20 00 20 00 20 00 20 00 ff 39 00 00 00 00 07 cc 04 8f 1f 88 1f e9 39 00 00 00 00 07 ce 1f c3 04 54 1f e9 39 00 00 00 00 07 cf 1f c3 1f 88 04 b5 39 00 00 00 00 09 c2 05 00 23 00 01 e0 03 20];
				gen-panel-mdnie-hbm-cmds = [39 00 00 00 00 09 c2 07 07 23 00 01 e0 03 20 39 00 00 00 00 12 c3 00 00 00 00 00 00 00 00 00 00 00 00 00 00 00 00 00 39 00 00 00 00 07 c4 00 ff ff 00 ff 00 39 00 00 00 00 07 c5 ff 00 00 ff ff 00 39 00 00 00 00 07 c6 ff 00 ff 00 00 ff 39 00 00 00 00 07 c7 ff 00 ff 00 ff 00 39 00 00 00 00 0d c8 00 17 00 17 00 17 00 17 00 17 04 9c 39 00 00 00 00 0d c9 04 9c 04 9c 00 18 00 18 00 18 00 18 39 00 00 00 00 0d ca 00 18 00 18 00 18 04 9a 06 9b 06 9b 39 00 00 00 00 0d cb 06 9b 09 9c 1e a0 56 a9 ef be 00 ff 39 00 00 00 00 07 cc 04 8f 1f 88 1f e9 39 00 00 00 00 07 ce 1f c3 04 54 1f e9 39 00 00 00 00 07 cf 1f c3 1f 88 04 b5 39 00 00 00 00 09 c2 07 00 23 00 01 e0 03 20];
			};
		};
	};

	sprd_vsp@60900000 {
		compatible = "sprd,sprd_vsp";
		reg = <0x60900000 0xc000>;
		interrupts = <0x00 0x2b 0x00>;
		clock-names = "clk_mm_i\0clk_vsp\0clk_parent_0\0clk_parent_1\0clk_parent_2";
		clocks = <0x23 0x39 0x1a 0x0c 0x0e>;
		clock-parent-info = <0x02 0x03>;
		version = <0x04>;
	};

	sprd_jpg {
		compatible = "sprd,sprd_jpg";
		reg = <0x60b00000 0x8000>;
		interrupts = <0x00 0x2a 0x00>;
		clock-names = "clk_mm_i\0clk_jpg";
		clocks = <0x23 0x3a>;
	};

	sec-smuic {
		gpios = <0x32 0x00 0x00 0x31 0x0e 0x00 0x31 0x0f 0x00>;
	};

	sprd-vibrator {
		vibr_voltage_set = <0xc8>;
	};

	i2c@70500000 {
		compatible = "sprd,i2c";
		interrupts = <0x00 0x0b 0x00>;
		reg = <0x70500000 0x1000>;
		#address-cells = <0x01>;
		#size-cells = <0x00>;

		sensor_main@0x3c {
			compatible = "sprd,sensor_main";
			reg = <0x3c>;
		};

		sensor_sub@0x21 {
			compatible = "sprd,sensor_sub";
			reg = <0x21>;
		};
	};

	i2c@70600000 {
		compatible = "sprd,i2c";
		interrupts = <0x00 0x0c 0x00>;
		reg = <0x70600000 0x1000>;
		#address-cells = <0x01>;
		#size-cells = <0x00>;
		pull_up_mode = <0x01>;

		ft6x06_ts@38 {
			compatible = "focaltech,ft6x06_ts";
			reg = <0x38>;
			interrupt-parent = <0x31>;
			interrupts = <0xe8 0x00>;
			ft6x06,x_resolution = <0x1df>;
			ft6x06,y_resolution = <0x31f>;
		};

		melfas_mip4@48 {
			compatible = "melfas,mip4_ts";
			reg = <0x48>;
			mip4_ts,irq-gpio = <0x31 0xe8 0x00>;
			mip4_ts,max_x = <0x1e0>;
			mip4_ts,max_y = <0x320>;
			mip4_ts,x_num = <0x04>;
			mip4_ts,y_num = <0x07>;
			mip4_ts,key_flag;
			mip4_ts,fw_name = "melfas/j1mini3g.fw";
			mip4_ts,ext_fw_name = "/sdcard/j1mini3g.bin";
		};
	};

	i2c@70700000 {
		compatible = "sprd,i2c";
		interrupts = <0x00 0x0d 0x00>;
		reg = <0x70700000 0x1000>;
		#address-cells = <0x01>;
		#size-cells = <0x00>;

		bma_acc@18 {
			compatible = "bma2x2";
			reg = <0x18>;
			interrupt-parent = <0x31>;
			interrupts = <0xee 0x00>;
			bma2x2,gpio_int1 = <0x31 0xee 0x00>;
			bma2x2,accel_place = <0x06>;
		};
	};

	i2c@70800000 {
		compatible = "sprd,i2c";
		interrupts = <0x00 0x0e 0x00>;
		reg = <0x70800000 0x1000>;
		#address-cells = <0x01>;
		#size-cells = <0x00>;
		status = "disabled";
	};

	i2c@70900000 {
		compatible = "sprd,i2c";
		interrupts = <0x00 0x0f 0x00>;
		reg = <0x70900000 0x1000>;
		#address-cells = <0x01>;
		#size-cells = <0x00>;
		status = "disabled";
	};

	i2c_gpio@0 {
		compatible = "i2c-gpio";
		interrupts = <0x00 0x0f 0x00>;
		reg = <0x70900000 0x1000>;
		#address-cells = <0x01>;
		#size-cells = <0x00>;
		gpios = <0x31 0x52 0x00 0x31 0x51 0x00>;
		i2c-gpio,delay-us = <0x0a>;
		i2c-gpio,timeout-ms = <0x00>;

		sm5504@14 {
			compatible = "SiliconMitus,sm5504";
			reg = <0x14>;
			interrupt-parent = <0x31>;
			sm5504,irq-gpio = <0x31 0xe9 0x00>;
		};
	};

	RT8547_flash {
		compatible = "Richtek,rt8547-fled";
		flen-gpio = <0x31 0xa7 0x00>;
		ctl-gpio = <0x31 0xa7 0x00>;
		flset-gpio = <0x31 0xa6 0x00>;
		fled,strobe_current = <0x3e8>;
		fled,timeout_current_level = <0x190>;
		fled,torch_current = <0x64>;
		fled,strobe_timeout = <0x4c0>;
		fled,lv_protection = <0xc1c>;
	};

	gps {
		compatible = "lsi,s5n6420";
		gps-pwr-en = <0x31 0xed 0x00>;
		gps-reset = <0x31 0xec 0x00>;
		gps-regulator = "vdd18";
		tcxo-regulator = "vddcammot";
		tcxo-regulator-volt = <0x325aa0>;
	};

	sprd_dcam {
		compatible = "sprd,sprd_dcam";
		interrupts = <0x00 0x2d 0x00>;
		reg = <0x60800000 0x100000>;
		clock-names = "clk_mm_i\0clk_dcam";
		clocks = <0x23 0x3b>;
	};

	sprd_scale {
		compatible = "sprd,sprd_scale";
	};

	sprd_rotation {
		compatible = "sprd,sprd_rotation";
	};

	sprd_sensor {
		compatible = "sprd,sprd_sensor";
		reg = <0x60c00000 0x100000>;
		gpios = <0x31 0xba 0x00 0x31 0xbc 0x00 0x31 0xe6 0x00 0x31 0xbb 0x00 0x31 0x00 0x00 0x31 0x00 0x00 0x31 0x00 0x00 0x31 0x00 0x00 0x31 0x00 0x00 0x31 0x00 0x00 0x31 0x00 0x00 0x31 0x00 0x00 0x31 0x00 0x00>;
		vdds = "vddcammot\0vddcama\0vddcamd\0vddcamio\0vddcammot\0vddcama\0vddcamd\0vddcamio";
		clock-names = "clk_mm_i\0clk_sensor\0clk_ccir\0clk_dcam\0clk_dcam_mipi";
		clocks = <0x23 0x3c 0x3d 0x3b 0x3e>;
	};

	sprd_isp {
		compatible = "sprd,sprd_isp";
		reg = <0x60a00000 0x100000>;
		clock-names = "clk_mm_i\0clk_isp";
		clocks = <0x23 0x3f>;
	};

	sprd_dma_copy {
		compatible = "sprd,sprd_dma_copy";
	};

	fb@20800000 {
		compatible = "sprd,sprdfb";
		reg = <0x20800000 0x1000 0x21800000 0x1000>;
		interrupts = <0x00 0x2e 0x00 0x00 0x30 0x00 0x00 0x31 0x00 0x00 0x2f 0x00>;
		clock-names = "dispc_clk_parent\0dispc_dbi_clk_parent\0dispc_dpi_clk_parent\0dispc_emc_clk_parent\0dispc_clk\0dispc_dbi_clk\0dispc_dpi_clk\0dispc_emc_clk\0fb_spi_clock\0fb_spi_clock_parent";
		clocks = <0x1b 0x1b 0x1d 0x19 0x40 0x41 0x42 0x43 0x44 0x09>;
		clock-src = <0xf424000 0xf424000 0x16e36000>;
		dpi_clk_div = <0x10>;
		sprd,fb_use_reservemem;
		sprd,fb_mem = <0x9f8ad000 0x465000>;
	};

	gsp@20a00000 {
		compatible = "sprd,gsp";
		reg = <0x20a00000 0x1000>;
		interrupts = <0x00 0x33 0x00>;
		clock-names = "clk_gsp\0clk_gsp_emc\0clk_gsp_parent\0clk_aon_apb";
		clocks = <0x45 0x46 0x1b 0x19>;
		gsp_mmu_ctrl_base = <0x21408000>;
	};

	sipc@0x87800000 {
		compatible = "sprd,sipc";
		reg = <0x87800000 0x200000>;
		#address-cells = <0x01>;
		#size-cells = <0x01>;
		ranges = <0x8000000 0x88000000 0x1c00000 0x7800000 0x87800000 0x140000 0x9bff000 0x89bff000 0x1000 0xa800000 0x8a800000 0x201000 0x7940000 0x87940000 0xc0000 0xaa00000 0x8aa00000 0x1000>;

		sipc_cpw@0x8000000 {
			sprd,name = "sipc-w";
			sprd,dst = <0x02>;
			sprd,ap2cp = "@,\0";
			sprd,cp2ap = <0x402c0004>;
			sprd,trig = <0x01>;
			sprd,clr = <0x01>;
			interrupts = <0x00 0x44 0x00>;
			reg = <0x8000000 0x1c00000 0x7800000 0x140000 0x9bff000 0x1000>;
		};
	};

	spipe-cpw {
		compatible = "sprd,spipe";
		sprd,name = "spipe_w";
		sprd,dst = <0x02>;
		sprd,channel = <0x04>;
		sprd,ringnr = <0x0b>;
		sprd,size-rxbuf = <0x1000>;
		sprd,size-txbuf = <0x1000>;
	};

	slog-cpw {
		compatible = "sprd,spipe";
		sprd,name = "slog_w";
		sprd,dst = <0x02>;
		sprd,channel = <0x05>;
		sprd,ringnr = <0x01>;
		sprd,size-rxbuf = <0x40000>;
		sprd,size-txbuf = <0x8000>;
	};

	stty-cpw {
		compatible = "sprd,spipe";
		sprd,name = "stty_w";
		sprd,dst = <0x02>;
		sprd,channel = <0x06>;
		sprd,ringnr = <0x20>;
		sprd,size-rxbuf = <0x800>;
		sprd,size-txbuf = <0x800>;
	};

	seth0-cpw {
		compatible = "sprd,seth";
		sprd,name = "rmnet0";
		sprd,dst = <0x02>;
		sprd,channel = <0x07>;
		sprd,blknum = <0x40>;
	};

	seth1-cpw {
		compatible = "sprd,seth";
		sprd,name = "rmnet1";
		sprd,dst = <0x02>;
		sprd,channel = <0x08>;
		sprd,blknum = <0x40>;
	};

	seth2-cpw {
		compatible = "sprd,seth";
		sprd,name = "rmnet2";
		sprd,dst = <0x02>;
		sprd,channel = <0x09>;
		sprd,blknum = <0x40>;
	};

	scproc@0x88000000 {
		compatible = "sprd,scproc";
		sprd,name = "cpw";
		sprd,ctrl-reg = <0x44 0x44 0xb0 0xff>;
		sprd,ctrl-mask = <0x2000000 0x10000000 0x01 0xf0000>;
		sprd,iram-data = <0xe59f0000 0xe12fff10 0x88300000>;
		reg = <0x88000000 0x1c00000 0x50000000 0x0c 0x402b0000 0x10000 0x402b0000 0x10000 0x402b0000 0x10000 0x402b0000 0x10000>;
		interrupts = <0x00 0x53 0x00>;
		#address-cells = <0x01>;
		#size-cells = <0x01>;
		ranges = <0x300000 0x88300000 0x800000 0x20000 0x88020000 0x220000>;

		modem@0x300000 {
			cproc,name = "modem";
			reg = <0x300000 0x800000>;
		};

		dsp@0x20000 {
			cproc,name = "dsp";
			reg = <0x20000 0x220000>;
		};
	};

	saudio_w {
		compatible = "sprd,saudio";
		sprd,saudio-dst-id = <0x02>;
		sprd,ctrl_channel = <0x0a>;
		sprd,playback_channel = <0x0b>;
		sprd,capture_channel = <0x0c>;
		sprd,monitor_channel = <0x0d>;
		sprd,saudio-names = "VIRTUAL AUDIO W";
	};

	saudio_voip {
		compatible = "sprd,saudio";
		sprd,saudio-dst-id = <0x02>;
		sprd,ctrl_channel = <0x0e>;
		sprd,playback_channel = <0x0f>;
		sprd,capture_channel = <0x10>;
		sprd,monitor_channel = <0x11>;
		sprd,saudio-names = "saudiovoip";
	};

	spipe_cpwcn {
		compatible = "sprd,spipe";
		sprd,name = "spipe_wcn";
		sprd,dst = <0x03>;
		sprd,channel = <0x04>;
		sprd,ringnr = <0x0c>;
		sprd,size-rxbuf = <0x1000>;
		sprd,size-txbuf = <0x1000>;
	};

	slog_cpwcn {
		compatible = "sprd,spipe";
		sprd,name = "slog_wcn";
		sprd,dst = <0x03>;
		sprd,channel = <0x05>;
		sprd,ringnr = <0x01>;
		sprd,size-rxbuf = <0x40000>;
		sprd,size-txbuf = <0x8000>;
	};

	stty4bt_cpwcn {
		compatible = "sprd,stty4bt";
		sprd,name = "sttybt";
		sprd,dst = <0x03>;
		sprd,channel = <0x04>;
		sprd,bufid = <0x0a>;
	};

	scproc@0x8a800000 {
		compatible = "sprd,scproc";
		sprd,name = "cpwcn";
		sprd,ctrl-reg = <0x68 0x68 0xb0 0xb0>;
		sprd,ctrl-mask = <0x2000000 0x10000000 0x04 0x04>;
		sprd,iram-data = <0xe59f0000 0xe12fff10 0x8a808000>;
		reg = <0x8a800000 0x201000 0x50003000 0x1000 0x402b0000 0x10000 0x402b0000 0x10000 0x402b0000 0x10000 0x402b0000 0x10000>;
		interrupts = <0x00 0x55 0x00>;
		#address-cells = <0x01>;
		#size-cells = <0x01>;
		ranges = <0x8000 0x8a808000 0x201000>;

		modem@0x8000 {
			cproc,name = "modem";
			reg = <0x8000 0x201000>;
		};
	};

	sprd_wlan {
		compatible = "sprd,sprd_wlan";
	};

	sdios {
		#address-cells = <0x01>;
		#size-cells = <0x01>;
		ranges;

		sdio@20600000 {
			compatible = "sprd,sdhost-3.0";
			reg = <0x20600000 0x1000>;
			interrupts = <0x00 0x3c 0x00>;
			sprd,name = "sdio_emmc";
			signal_default_Voltage = <0x1b7740>;
			ocr_avail = <0x40000>;
			clocks = <0x47 0x1a>;
			base_clk = <0xb71b000>;
			caps = <0xc00f8d47>;
			caps2 = <0x202>;
			pm_caps = <0x04>;
			writeDelay = <0x1b>;
			readPosDelay = <0x0c>;
			readNegDelay = <0x0c>;
		};

		sdio@20300000 {
			compatible = "sprd,sdhost-3.0";
			reg = <0x20300000 0x1000>;
			interrupts = <0x00 0x39 0x00>;
			sprd,name = "sdio_sd";
			detect_gpio = <0x47>;
			SD_Pwr_Name = "vddsdcore";
			_1_8V_signal_Name = "vddsdio";
			signal_default_Voltage = <0x2dc6c0>;
			ocr_avail = <0x40000>;
			clocks = <0x48 0x1a>;
			base_clk = <0xb71b000>;
			caps = <0xc0000407>;
			caps2 = <0x200>;
			pm_caps = <0x04>;
			writeDelay = <0x03>;
			readPosDelay = <0x03>;
			readNegDelay = <0x03>;
		};

		sdio@20400000 {
			compatible = "sprd,sdhost-3.0";
			reg = <0x20400000 0x1000>;
			interrupts = <0x00 0x3a 0x00>;
			sprd,name = "sdio_wifi";
			ocr_avail = <0x360080>;
			clocks = <0x49 0x0e>;
			base_clk = <0x5b8d800>;
			caps = <0xc00fa407>;
			caps2 = <0x00>;
			pm_caps = <0x05>;
			writeDelay = <0x03>;
			readPosDelay = <0x03>;
			readNegDelay = <0x03>;
		};
	};

	usb@20200000 {
		compatible = "sprd,usb";
		interrupts = <0x00 0x37 0x00>;
		ngpios = <0x02>;
		gpios = <0x32 0x00 0x00 0x31 0x48 0x00>;
		reg = <0x20200000 0x1000>;
		tune_value = <0xd2200020>;
		tune_ctrl1_value = <0x1ac0>;
		usb-supply = <0x4a>;
		#address-cells = <0x01>;
		#size-cells = <0x00>;
	};

	usb_notifier {
		compatible = "samsung,usb-notifier";
		booster-name = "sm5701_booster";
	};

	sprd_thermal {
		compatible = "sprd,sprd-thermal";
		id = <0x00>;
		interrupts = <0x00 0x1a 0x00>;
		reg = <0x402f0000 0x1000>;
		trip_points_active = <0x41 0x45 0x5f 0x6e>;
		trip_points_lowoff = <0x00 0x39 0x3d 0x50>;
		trip_points_critical = <0x6e>;
		trip_num = <0x05>;
	};

	sprd_cpu_cooling {
		compatible = "sprd,sprd-cpu-cooling";
		id = <0x00>;
		max_freq = <0x124f80 0x124f80 0xc67c8 0xc67c8>;
		max_core = <0x04 0x04 0x04 0x01>;
		state_num = <0x04>;
	};

	spi@70a00000 {
		compatible = "sprd,sprd-spi";
		interrupts = <0x00 0x07 0x00>;
		reg = <0x70a00000 0x1000>;
		clock-names = "clk_spi0";
		#address-cells = <0x01>;
		#size-cells = <0x00>;
		status = "disabled";
	};

	spi@70b00000 {
		compatible = "sprd,sprd-spi";
		interrupts = <0x00 0x08 0x00>;
		reg = <0x70b00000 0x1000>;
		clock-names = "clk_spi1";
		#address-cells = <0x01>;
		#size-cells = <0x00>;
		status = "disabled";
	};

	spi@70c00000 {
		compatible = "sprd,sprd-spi";
		interrupts = <0x00 0x09 0x00>;
		reg = <0x70c00000 0x1000>;
		clock-names = "clk_spi2";
		#address-cells = <0x01>;
		#size-cells = <0x00>;
		status = "disabled";
	};

	dmac@20100000 {
		compatible = "sprd,sprd-dma";
		interrupts = <0x00 0x32 0x00>;
		reg = <0x20100000 0x4000>;
	};

	adc@40038300 {
		compatible = "sprd,sprd-adc";
		reg = <0x40038300 0x400>;
	};

	hwspinlock0@20c00000 {
		compatible = "sprd,sprd-hwspinlock";
		reg = <0x20c00000 0x1000>;
	};

	hwspinlock1@40060000 {
		compatible = "sprd,sprd-hwspinlock";
		reg = <0x40060000 0x1000>;
	};

	gpu@60000000 {
		compatible = "arm,mali-400\0arm,mali-utgard";
		reg = <0x60000000 0x10000>;
		interrupts = <0x00 0x27 0x00 0x00 0x27 0x00 0x00 0x27 0x00 0x00 0x27 0x00 0x00 0x27 0x00>;
		interrupt-names = "IRQGP\0IRQGPMMU\0IRQPP0\0IRQPPMMU0\0IRQPMU";
		pmu_domain_config = <0x1000 0x1000 0x00 0x00 0x00 0x00 0x00 0x00 0x00 0x1000 0x00 0x00>;
		pmu_switch_delay = <0xffff>;
		clocks = <0x4b 0x4c 0x0d 0x20 0x1b 0x1c 0x1d 0x21 0x22>;
		clock-names = "clk_gpu_axi\0clk_gpu\0clk_153m6\0clk_208m\0clk_256m\0clk_312m\0clk_384m\0clk_460m8\0clk_512m";
		freq-list-len = <0x04>;
		freq-lists = <0x25800 0x02 0x01 0x3e800 0x04 0x01 0x5dc00 0x06 0x01 0x7d000 0x08 0x01>;
		freq-default = <0x01>;
		freq-9 = <0x02>;
		freq-8 = <0x01>;
		freq-7 = <0x00>;
		freq-5 = <0x00>;
		freq-range-max = <0x03>;
		freq-range-min = <0x00>;
	};

	ion {
		compatible = "sprd,ion-sprd";
		#address-cells = <0x01>;
		#size-cells = <0x00>;

		sprd,ion-heap@1 {
			reg = <0x01>;
			reg-names = "ion_heap_system";
			sprd,ion-heap-type = <0x00>;
			sprd,ion-heap-mem = <0x00 0x00>;
		};

		sprd,ion-heap@2 {
			reg = <0x02>;
			reg-names = "ion_heap_carveout_mm";
			sprd,ion-heap-type = <0x00>;
			sprd,ion-heap-mem = <0x98800000 0x7100000>;
		};

		sprd,ion-heap@3 {
			reg = <0x03>;
			reg-names = "ion_heap_carveout_overlay";
			sprd,ion-heap-type = <0x02>;
			sprd,ion-heap-mem = <0x9fd12000 0x2ee000>;
		};
	};

	sprd_iommu@21400000 {
		compatible = "sprd,sprd_iommu";
		func-name = "sprd_iommu_gsp";
		reg = <0x10000000 0x2000000 0x21400000 0x8000 0x21408000 0x8000>;
		reg_name = "iova\0pgt\0ctrl_reg";
		clock-names = "clk_gsp_emc\0clk_153m6\0clk_gsp";
		clocks = <0x46 0x0d 0x45>;
		status = "ok";
	};

	sprd_iommu@60f00000 {
		compatible = "sprd,sprd_iommu";
		func-name = "sprd_iommu_mm";
		reg = <0x20000000 0x8000000 0x60f00000 0x20000 0x60f20000 0x2000>;
		reg_name = "iova\0pgt\0ctrl_reg";
		clock-names = "clk_mmu\0clk_mm_i";
		clocks = <0x4d 0x23>;
		status = "ok";
	};

	sprd-io-base {
		#address-cells = <0x01>;
		#size-cells = <0x01>;
		ranges = <0x00 0x00 0x80000000>;

		ahb {
			compatible = "sprd,ahb";
			reg = <0x20d00000 0x10000>;
		};

		aonapb {
			compatible = "sprd,aonapb";
			reg = <0x402e0000 0x10000>;
		};

		apbreg {
			compatible = "sprd,apbreg";
			reg = <0x71300000 0x10000>;
		};

		pmu {
			compatible = "sprd,pmu";
			reg = <0x402b0000 0x10000>;
		};

		mmahb {
			compatible = "sprd,mmahb";
			reg = <0x60d00000 0x4000>;
		};

		mmckg {
			compatible = "sprd,mmckg";
			reg = <0x60e00000 0x1000>;
		};

		adislave {
			compatible = "sprd,adislave";
			reg = <0x40038000 0x1000>;
		};

		gpuapb {
			compatible = "sprd,gpuapb";
			reg = <0x60100000 0x1000>;
		};

		aonckg {
			compatible = "sprd,aonckg";
			reg = <0x402d0000 0x1000>;
		};

		apbckg {
			compatible = "sprd,apbckg";
			reg = <0x71200000 0x10000>;
		};

		coresight {
			compatible = "sprd,coresight";
			reg = <0x10000000 0x400000>;
		};

		core {
			compatible = "sprd,core";
			reg = <0x12000000 0x10000>;
		};

		int {
			compatible = "sprd,int";
			reg = <0x40200000 0x1000>;
		};

		intc0 {
			compatible = "sprd,intc0";
			reg = <0x71400000 0x1000>;
		};

		intc1 {
			compatible = "sprd,intc1";
			reg = <0x71500000 0x1000>;
		};

		intc2 {
			compatible = "sprd,intc2";
			reg = <0x71600000 0x1000>;
		};

		intc3 {
			compatible = "sprd,intc3";
			reg = <0x71700000 0x1000>;
		};

		uidefuse {
			compatible = "sprd,uidefuse";
			reg = <0x40240000 0x1000>;
		};

		isp {
			compatible = "sprd,isp";
			reg = <0x60a00000 0x8000>;
		};

		ca7wdg {
			compatible = "sprd,ca7wdg";
			reg = <0x40320000 0x1000>;
		};

		csi2 {
			compatible = "sprd,csi2";
			reg = <0x60c00000 0x1000>;
		};

		wdg {
			compatible = "sprd,wdg";
			reg = <0x40290000 0x1000>;
		};

		ipi {
			compatible = "sprd,ipi";
			reg = <0x402c0000 0x1000>;
		};

		dcam {
			compatible = "sprd,dcam";
			reg = <0x60800000 0x10000>;
		};

		syscnt {
			compatible = "sprd,syscnt";
			reg = <0x40230000 0x1000>;
		};

		dma0 {
			compatible = "sprd,dma0";
			reg = <0x20100000 0x4000>;
		};

		pub {
			compatible = "sprd,pub";
			reg = <0x300e0000 0x10000>;
		};

		pin {
			compatible = "sprd,pin";
			reg = <0x402a0000 0x1000>;
		};

		axibm0 {
			compatible = "sprd,axibm0";
			reg = <0x00 0x30040000 0x00 0x20000>;
			interrupts = <0x00 0x56 0x00>;
		};
	};

	sprd_bm {
		compatible = "sprd,sprd_bm";
		reg = <0x30040000 0xa0000 0x20e00000 0x300000>;
		interrupts = <0x00 0x56 0x00>;
		sprd,bm_status = <0x01>;
		sprd,bm_count = <0x0a 0x0a>;
		sprd,mm_chn = <0x00 0x01>;
		sprd,gpu_chn = <0x01 0x01>;
		sprd,disp_chn = <0x02 0x01>;
		sprd,cpu_chn = <0x03 0x01>;
		sprd,cp0_arm1_chn = <0x04 0x01>;
		sprd,cp0_arm0_chn = <0x05 0x01>;
		sprd,ap_chn = <0x06 0x01>;
		sprd,zip_chn = <0x07 0x01>;
		sprd,cp2_chn = <0x08 0x01>;
		sprd,cp0_dsp_chn = <0x09 0x01>;
		sprd,ap_cpu_chn = <0x00 0x00>;
		sprd,ap_dap_chn = <0x00 0x01>;
		sprd,ap_dma_w_chn = <0x01 0x00>;
		sprd,ap_dma_r_chn = <0x01 0x01>;
		sprd,ap_sdio_0_chn = <0x01 0x02>;
		sprd,ap_sdio_1_chn = <0x01 0x03>;
		sprd,ap_emmc_chn = <0x02 0x00>;
		sprd,ap_sdio_2_chn = <0x02 0x01>;
		sprd,ap_nfc_chn = <0x02 0x02>;
		sprd,ap_usb_chn = <0x02 0x03>;
	};

	wdt@40290000 {
		compatible = "sprd,sprd-wdt";
		reg = <0x40290000 0x1000 0x40320000 0x1000>;
		interrupts = <0x00 0x7c 0x00>;
	};

	sprd-marlin {
		compatible = "sprd,marlin";
		gpios = <0x31 0x3b 0x00 0x31 0x3a 0x00 0x31 0x39 0x00 0x31 0x2f 0x00 0x31 0x38 0x00>;
		cp-rfctl-offset = <0xd8>;
		vdd-download = "vddcon";
		vdd-pa = "vddwifipa";
		clk-name = "clk_aux0";
		sdhci-name = "sdio_wifi";
	};

	input_booster {
		status = "disabled";
		compatible = "input_booster";
		#address-cells = <0x01>;
		#size-cells = <0x00>;

		booster_key@1 {
			input_booster,label = "KEY";
			input_booster,type = <0x00>;
			input_booster,levels = <0x01>;
			input_booster,cpu_freqs = <0x124f80>;
			input_booster,core_num_lock = <0x03>;
			input_booster,head_times = <0xc8>;
			input_booster,tail_times = <0x00>;
		};

		booster_key@2 {
			input_booster,label = "TOUCHKEY";
			input_booster,type = <0x01>;
			input_booster,levels = <0x01>;
			input_booster,cpu_freqs = <0xbb800>;
			input_booster,core_num_lock = <0x03>;
			input_booster,head_times = <0x00>;
			input_booster,tail_times = <0x12c>;
		};

		booster_key@3 {
			input_booster,label = "TOUCH";
			input_booster,type = <0x02>;
			input_booster,levels = <0x01 0x02 0x03>;
			input_booster,cpu_freqs = <0x124f80 0x124f80 0xbb800>;
			input_booster,core_num_lock = <0x03 0x03 0x03>;
			input_booster,head_times = <0xc8 0xc8 0x00>;
			input_booster,tail_times = <0x00 0x00 0x12c>;
		};

		booster_key@4 {
			input_booster,label = "MULTITOUCH";
			input_booster,type = <0x03>;
			input_booster,levels = <0x01 0x02>;
			input_booster,cpu_freqs = <0x124f80 0x124f80>;
			input_booster,core_num_lock = <0x04 0x04>;
			input_booster,head_times = <0x3e8 0x00>;
			input_booster,tail_times = <0x00 0x1f4>;
		};

		booster_key@5 {
			input_booster,label = "KEYBOARD";
			input_booster,type = <0x04>;
			input_booster,levels = <0x01 0x02>;
			input_booster,cpu_freqs = <0x124f80 0x124f80>;
			input_booster,core_num_lock = <0x03 0x03>;
			input_booster,head_times = <0xc8 0xc8>;
			input_booster,tail_times = <0x00 0x00>;
		};

		booster_key@6 {
			input_booster,label = "MOUSE";
			input_booster,type = <0x05>;
			input_booster,levels = <0x01 0x02>;
			input_booster,cpu_freqs = <0x124f80 0xbb800>;
			input_booster,core_num_lock = <0x03 0x03>;
			input_booster,head_times = <0xc8 0x00>;
			input_booster,tail_times = <0x00 0x12c>;
		};

		booster_key@7 {
			input_booster,label = "MOUSE WHEEL";
			input_booster,type = <0x06>;
			input_booster,levels = <0x01 0x02>;
			input_booster,cpu_freqs = <0x124f80 0x00>;
			input_booster,core_num_lock = <0x03 0x03>;
			input_booster,head_times = <0xc8 0x00>;
			input_booster,tail_times = <0x00 0x00>;
		};

		booster_key@8 {
			input_booster,label = "PEN HOVER";
			input_booster,type = <0x07>;
			input_booster,levels = <0x01 0x02>;
			input_booster,cpu_freqs = <0x124f80 0xbb800>;
			input_booster,core_num_lock = <0x03 0x03>;
			input_booster,head_times = <0xc8 0x00>;
			input_booster,tail_times = <0x00 0x12c>;
		};
	};
};
